VERSION ""

NS_ :

BS_:

BU_: VCU ADCU

BO_ 1544 mGpsAntStatus: 2 ADCU
 SG_ RelPosLength : 0|16@1- (0.001,0) [-32.768|32.767] "m"  VCU

BO_ 1543 mGpsLonRoverHP: 6 ADCU
 SG_ VehLonRover_hi : 16|32@1- (1,0) [-2147483648|2147483647] ""  VCU
 SG_ VehLonRover_lo : 0|16@1+ (1,0) [0|65535] ""  VCU

BO_ 1542 mGpsLatRoverHP: 6 ADCU
 SG_ VehLatRover_lo : 0|16@1+ (1,0) [0|65535] ""  VCU
 SG_ VehLatRover_hi : 16|32@1- (1,0) [-2147483648|2147483647] ""  VCU

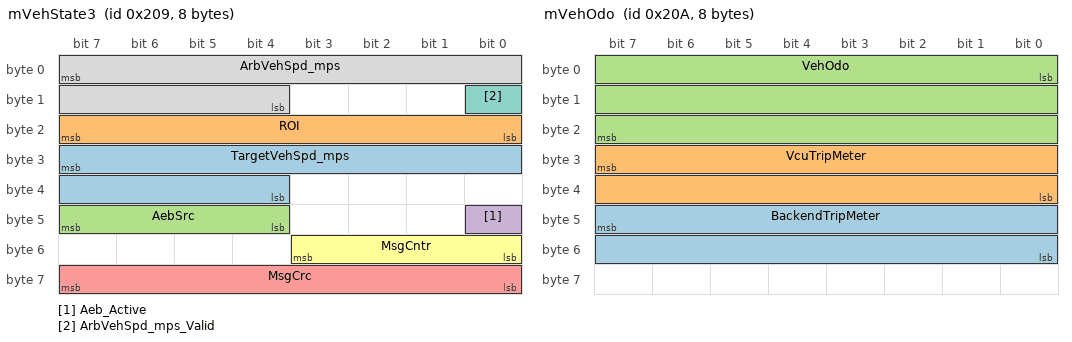
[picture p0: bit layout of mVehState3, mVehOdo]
BO_ 521 mVehState3: 8 VCU
 SG_ TargetVehSpd_mps : 31|12@0- (0.01,0) [-20.48|20.47] "mps"  ADCU
 SG_ ROI : 23|8@0- (0.01,0) [-1.28|1.27] ""  ADCU
 SG_ AebSrc : 47|4@0+ (1,0) [0|15] ""  ADCU
 SG_ Aeb_Active : 40|1@0+ (1,0) [0|0] ""  ADCU
 SG_ MsgCrc : 63|8@0+ (1,0) [0|255] ""  ADCU
 SG_ MsgCntr : 51|4@0+ (1,0) [0|15] ""  ADCU
 SG_ ArbVehSpd_mps_Valid : 8|1@0+ (1,0) [0|0] ""  ADCU
 SG_ ArbVehSpd_mps : 7|12@0- (0.01,0) [-20.48|20.47] "mps"  ADCU

BO_ 522 mVehOdo: 8 VCU
 SG_ BackendTripMeter : 47|16@0+ (0.001,0) [0|65.535] "Km"  ADCU
 SG_ VcuTripMeter : 31|16@0+ (0.001,0) [0|65.535] "Km"  ADCU
 SG_ VehOdo : 0|24@1+ (0.001,0) [0|16777.213] "Km"  ADCU

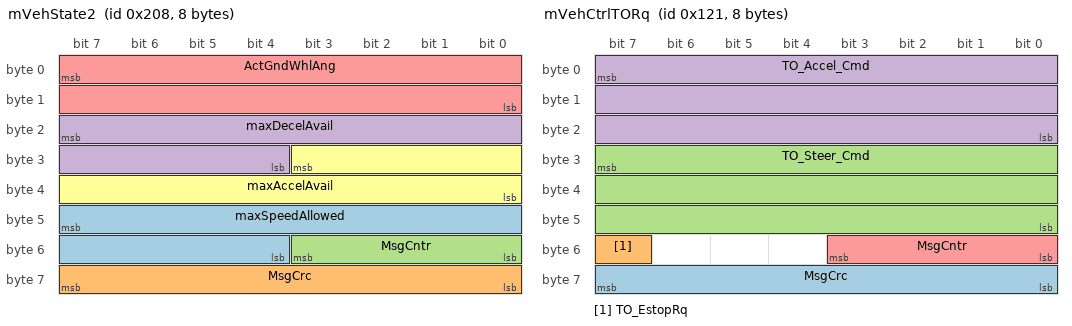
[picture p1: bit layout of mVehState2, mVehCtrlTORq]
BO_ 520 mVehState2: 8 VCU
 SG_ maxSpeedAllowed : 47|12@0+ (0.015625,0) [0|63.984375] "m/s"  ADCU
 SG_ MsgCrc : 56|8@1+ (1,0) [0|255] ""  ADCU
 SG_ MsgCntr : 48|4@1+ (1,0) [0|15] ""  ADCU
 SG_ maxDecelAvail : 23|12@0- (0.015625,0) [-32|31.984375] "m/s2"  ADCU
 SG_ ActGndWhlAng : 7|16@0- (0.01,0) [-327.68|327.67] "deg"  ADCU
 SG_ maxAccelAvail : 27|12@0- (0.015625,0) [-32|31.984375] "m/s2"  ADCU

BO_ 289 mVehCtrlTORq: 8 VCU
 SG_ MsgCrc : 63|8@0+ (1,0) [0|255] ""  ADCU
 SG_ TO_EstopRq : 55|1@0+ (1,0) [0|1] ""  ADCU
 SG_ TO_Steer_Cmd : 31|24@0- (1E-06,0) [-1|1] ""  ADCU
 SG_ TO_Accel_Cmd : 7|24@0- (1E-06,0) [-1|1] ""  ADCU
 SG_ MsgCntr : 51|4@0+ (1,0) [0|15] ""  ADCU

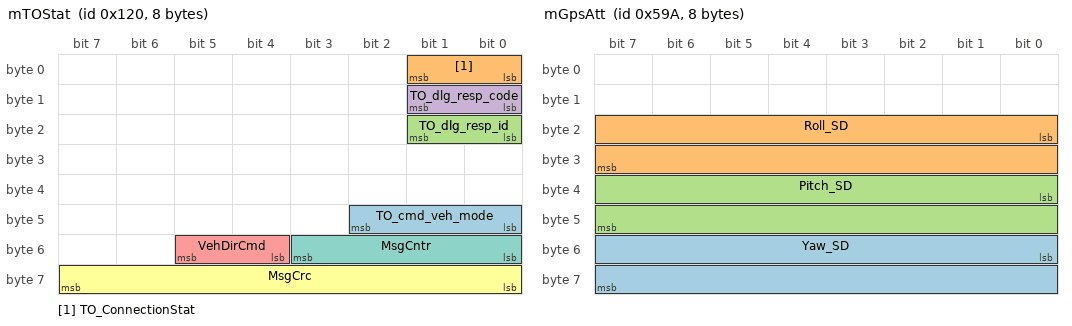
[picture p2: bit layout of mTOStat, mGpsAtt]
BO_ 288 mTOStat: 8 VCU
 SG_ TO_cmd_veh_mode : 42|3@0+ (1,0) [0|7] ""  ADCU
 SG_ TO_ConnectionStat : 1|2@0+ (1,0) [0|2] ""  ADCU
 SG_ TO_dlg_resp_id : 17|2@0+ (1,0) [0|3] ""  ADCU
 SG_ TO_dlg_resp_code : 9|2@0+ (1,0) [0|3] ""  ADCU
 SG_ VehDirCmd : 53|2@0+ (1,0) [0|0] ""  ADCU
 SG_ MsgCrc : 63|8@0+ (1,0) [0|255] ""  ADCU
 SG_ MsgCntr : 51|4@0+ (1,0) [0|15] ""  ADCU

BO_ 1541 mGpsLonHP: 8 ADCU
 SG_ VehLon_lo : 0|16@1+ (1,0) [0|65535] ""  VCU
 SG_ VehLon_hi : 16|32@1- (1,0) [-2147483648|2147483647] ""  VCU

BO_ 1540 mGpsLatHP: 8 ADCU
 SG_ VehLat_lo : 0|16@1+ (1,0) [0|65535] ""  VCU
 SG_ VehLat_hi : 16|32@1- (1,0) [-2147483648|2147483647] ""  VCU

BO_ 1429 mGpsSpdNorth: 8 ADCU
 SG_ NorthVelocity : 16|32@1- (0.001,0) [-2147483.648|2147483.645] "m/s"  VCU

BO_ 1428 mGpsSpdEast: 8 ADCU
 SG_ EastVelocity : 16|32@1- (0.001,0) [-2147483.648|2147483.645] "m/s"  VCU

BO_ 1434 mGpsAtt: 8 ADCU
 SG_ Yaw_SD : 48|16@1- (0.001,0) [0|0] ""  VCU
 SG_ Roll_SD : 16|16@1- (0.001,0) [0|0] ""  VCU
 SG_ Pitch_SD : 32|16@1- (0.001,0) [0|0] ""  VCU

BO_ 1425 mGpsSpdVeh: 8 ADCU
 SG_ gSpeed : 32|32@1+ (0.001,0) [0|100] "m/s"  VCU
 SG_ Yaw : 0|16@1+ (0.01,0) [0|655.35] "deg"  VCU

BO_ 1437 mGpsTime: 8 ADCU
 SG_ TimeStamp : 0|32@1+ (0.1,0) [0|429496729.5] "ms"  VCU
 SG_ UTC : 32|32@1+ (1,0) [0|4294967295] "s"  VCU

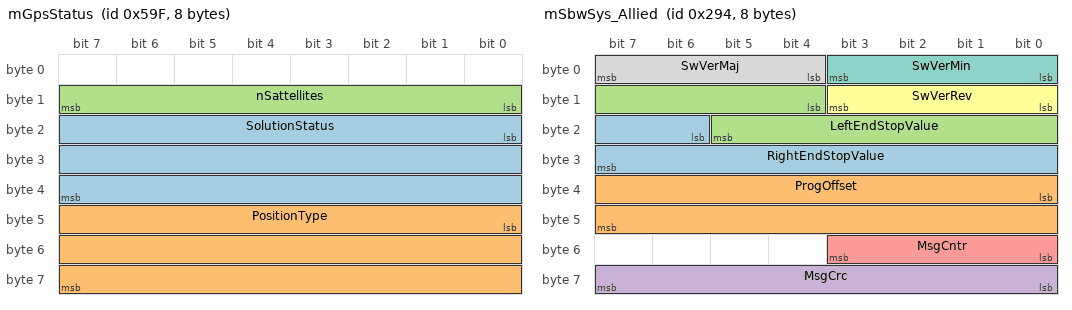
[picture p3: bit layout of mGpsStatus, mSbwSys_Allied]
BO_ 1439 mGpsStatus: 8 ADCU
 SG_ SolutionStatus : 16|24@1+ (1,0) [0|0] ""  VCU
 SG_ PositionType : 40|24@1+ (1,0) [0|0] ""  VCU
 SG_ nSattellites : 8|8@1+ (1,0) [0|0] ""  VCU

BO_ 660 mSbwSys_Allied: 8 VCU
 SG_ RightEndStopValue : 22|10@1+ (-1,0) [-1023|0] "deg"  ADCU
 SG_ ProgOffset : 32|16@1- (0.01,0) [-327.68|327.67] "deg"  ADCU
 SG_ LeftEndStopValue : 12|10@1+ (1,0) [0|1023] "deg"  ADCU
 SG_ MsgCrc : 56|8@1+ (1,0) [0|255] ""  ADCU
 SG_ MsgCntr : 48|4@1+ (1,0) [0|15] ""  ADCU
 SG_ SwVerRev : 8|4@1+ (1,0) [0|15] ""  ADCU
 SG_ SwVerMin : 0|4@1+ (1,0) [0|15] ""  ADCU
 SG_ SwVerMaj : 4|4@1+ (1,0) [0|15] ""  ADCU

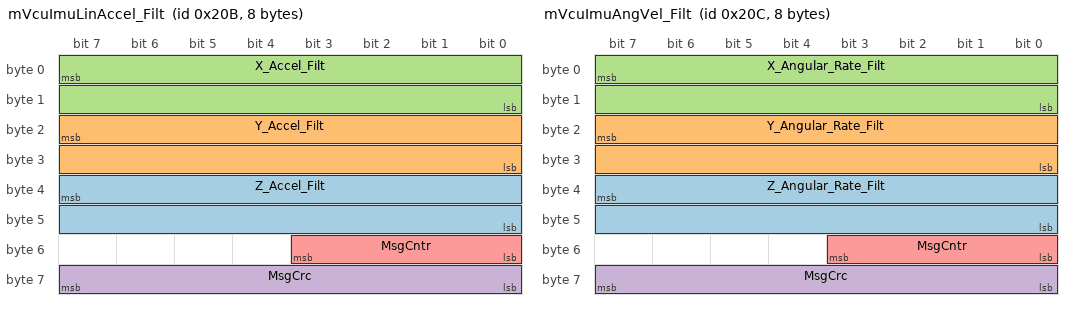
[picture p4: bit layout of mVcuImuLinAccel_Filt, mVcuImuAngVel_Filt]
BO_ 523 mVcuImuLinAccel_Filt: 8 VCU
 SG_ Z_Accel_Filt : 39|16@0- (0.001,0) [-32.768|32.767] "m/s2"  ADCU
 SG_ Y_Accel_Filt : 23|16@0- (0.001,0) [-32.768|32.767] "m/s2"  ADCU
 SG_ X_Accel_Filt : 7|16@0- (0.001,0) [-32.768|32.767] "m/s2"  ADCU
 SG_ MsgCrc : 63|8@0+ (1,0) [0|255] ""  ADCU
 SG_ MsgCntr : 51|4@0+ (1,0) [0|15] ""  ADCU

BO_ 524 mVcuImuAngVel_Filt: 8 VCU
 SG_ Z_Angular_Rate_Filt : 39|16@0- (0.01,0) [-327.68|327.67] "deg/s"  ADCU
 SG_ Y_Angular_Rate_Filt : 23|16@0- (0.01,0) [-327.68|327.67] "deg/s"  ADCU
 SG_ X_Angular_Rate_Filt : 7|16@0- (0.01,0) [-327.68|327.67] "deg/s"  ADCU
 SG_ MsgCrc : 63|8@0+ (1,0) [0|255] ""  ADCU
 SG_ MsgCntr : 51|4@0+ (1,0) [0|15] ""  ADCU

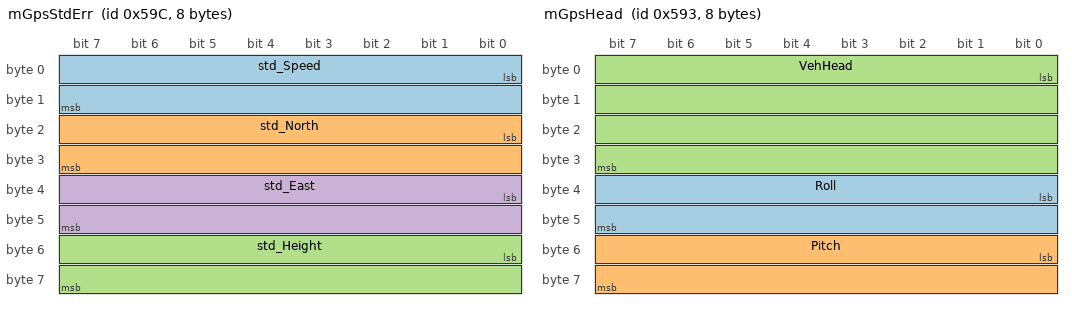
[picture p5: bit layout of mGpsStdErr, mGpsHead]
BO_ 1436 mGpsStdErr: 8 ADCU
 SG_ std_Speed : 0|16@1+ (0.001,0) [0|65.533] "m/s"  VCU
 SG_ std_North : 16|16@1+ (0.001,0) [0|65.533] "m"  VCU
 SG_ std_Height : 48|16@1+ (0.001,0) [0|65.533] "m"  VCU
 SG_ std_East : 32|16@1+ (0.001,0) [0|65.533] "m"  VCU

BO_ 1427 mGpsHead: 8 ADCU
 SG_ Roll : 32|16@1- (0.01,0) [-327.68|327.65] "deg"  VCU
 SG_ Pitch : 48|16@1- (0.01,0) [-327.68|327.65] "deg"  VCU
 SG_ VehHead : 0|32@1+ (1E-05,0) [0|360] "deg"  VCU

BO_ 1433 mGpsHeight: 8 ADCU
 SG_ Height : 16|32@1- (0.001,0) [-2147483.648|2147483.645] "m"  VCU

BO_ 1432 mGpsLat: 8 ADCU
 SG_ VehLat : 16|48@1- (3.27418092638254E-10,0) [-90|90] ""  VCU

BO_ 1431 mGpsLong: 8 ADCU
 SG_ VehLong : 16|48@1- (3.27418092638254E-10,0) [-180|180] ""  VCU

BO_ 519 mAdcuFaults: 8 ADCU
 SG_ Flt_EPVMC_Cameras : 0|1@0+ (1,0) [0|0] ""  VCU

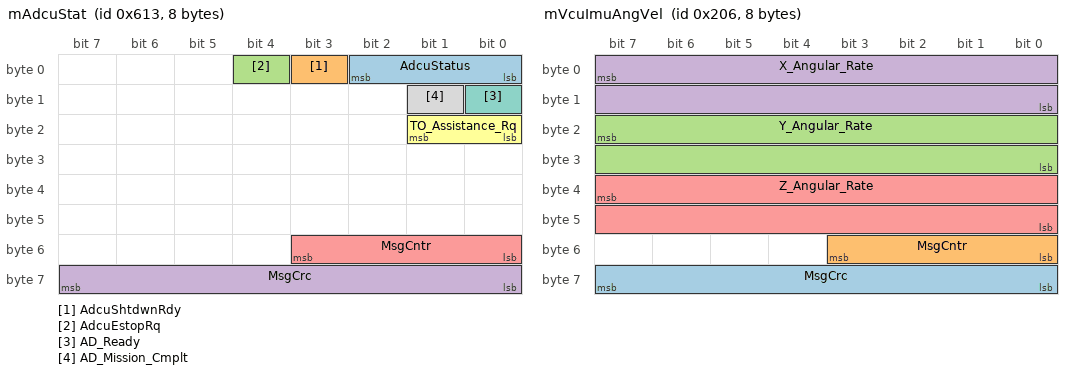
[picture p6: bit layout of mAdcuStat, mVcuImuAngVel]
BO_ 1555 mAdcuStat: 8 ADCU
 SG_ AdcuStatus : 2|3@0+ (1,0) [0|7] ""  VCU
 SG_ AdcuShtdwnRdy : 3|1@0+ (1,0) [0|1] ""  VCU
 SG_ AdcuEstopRq : 4|1@0+ (1,0) [0|1] ""  VCU
 SG_ MsgCrc : 63|8@0+ (1,0) [0|255] ""  VCU
 SG_ MsgCntr : 51|4@0+ (1,0) [0|15] ""  VCU
 SG_ TO_Assistance_Rq : 17|2@0+ (1,0) [0|2] ""  VCU
 SG_ AD_Ready : 8|1@0+ (1,0) [0|0] ""  VCU
 SG_ AD_Mission_Cmplt : 9|1@0+ (1,0) [0|1] ""  VCU

BO_ 518 mVcuImuAngVel: 8 VCU
 SG_ MsgCrc : 63|8@0+ (1,0) [0|255] ""  ADCU
 SG_ MsgCntr : 51|4@0+ (1,0) [0|15] ""  ADCU
 SG_ Y_Angular_Rate : 23|16@0- (0.01,0) [-327.68|327.67] "deg/s"  ADCU
 SG_ X_Angular_Rate : 7|16@0- (0.01,0) [-327.68|327.67] "deg/s"  ADCU
 SG_ Z_Angular_Rate : 39|16@0- (0.01,0) [-327.68|327.67] "deg/s"  ADCU

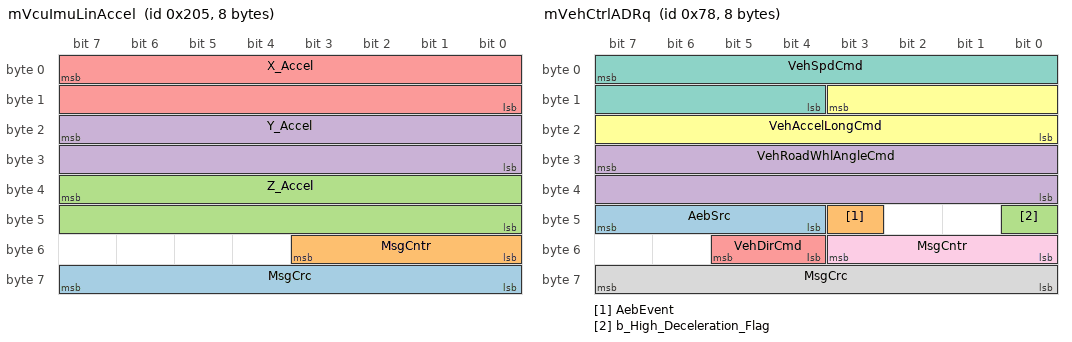
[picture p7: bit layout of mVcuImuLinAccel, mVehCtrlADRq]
BO_ 517 mVcuImuLinAccel: 8 VCU
 SG_ MsgCrc : 63|8@0+ (1,0) [0|255] ""  ADCU
 SG_ MsgCntr : 51|4@0+ (1,0) [0|15] ""  ADCU
 SG_ Z_Accel : 39|16@0- (0.001,0) [-32.768|32.767] "m/s2"  ADCU
 SG_ Y_Accel : 23|16@0- (0.001,0) [-32.768|32.767] "m/s2"  ADCU
 SG_ X_Accel : 7|16@0- (0.001,0) [-32.768|32.767] "m/s2"  ADCU

BO_ 120 mVehCtrlADRq: 8 ADCU
 SG_ AebSrc : 47|4@0+ (1,0) [0|15] ""  VCU
 SG_ AebEvent : 43|1@0+ (1,0) [0|1] ""  VCU
 SG_ b_High_Deceleration_Flag : 40|1@0+ (1,0) [0|1] ""  VCU
 SG_ VehRoadWhlAngleCmd : 31|16@0- (0.01,0) [-327.68|327.67] "deg"  VCU
 SG_ VehDirCmd : 53|2@0+ (1,0) [0|0] ""  VCU
 SG_ VehAccelLongCmd : 11|12@0- (0.015625,0) [-32|31.984375] "m/s2"  VCU
 SG_ VehSpdCmd : 7|12@0- (0.015625,0) [-64|63.96875] "m/s"  VCU
 SG_ MsgCrc : 63|8@0+ (1,0) [0|255] ""  VCU
 SG_ MsgCntr : 51|4@0+ (1,0) [0|15] ""  VCU

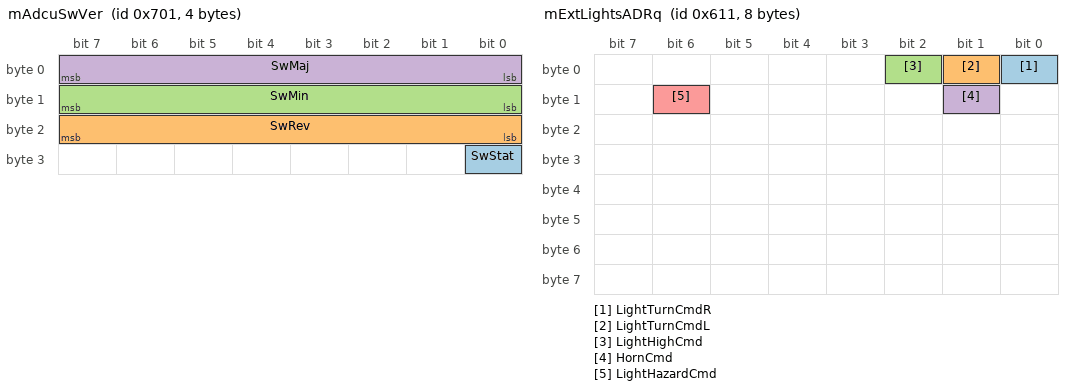
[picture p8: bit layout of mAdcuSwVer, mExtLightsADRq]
BO_ 1793 mAdcuSwVer: 4 ADCU
 SG_ SwStat : 24|1@0+ (1,0) [0|1] ""  VCU
 SG_ SwRev : 23|8@0+ (1,0) [0|255] ""  VCU
 SG_ SwMin : 15|8@0+ (1,0) [0|255] ""  VCU
 SG_ SwMaj : 7|8@0+ (1,0) [0|255] ""  VCU

BO_ 1553 mExtLightsADRq: 8 ADCU
 SG_ LightTurnCmdR : 0|1@1+ (1,0) [0|1] ""  VCU
 SG_ LightTurnCmdL : 1|1@1+ (1,0) [0|1] ""  VCU
 SG_ LightHighCmd : 2|1@1+ (1,0) [0|1] ""  VCU
 SG_ HornCmd : 9|1@1+ (1,0) [0|1] ""  VCU
 SG_ LightHazardCmd : 14|1@0+ (1,0) [0|1] ""  VCU

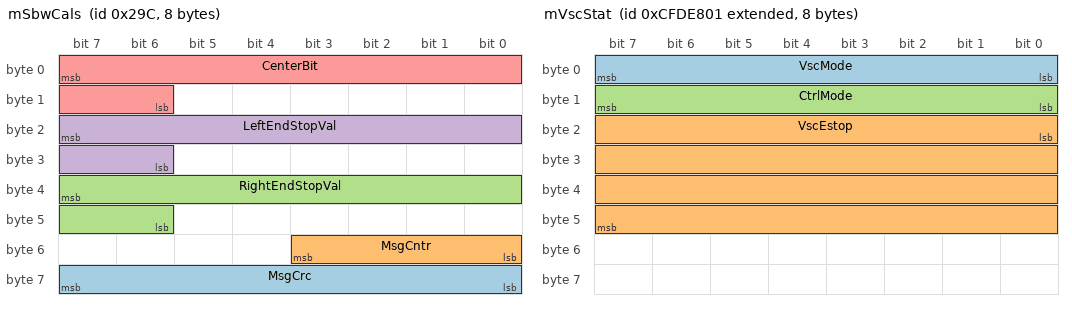
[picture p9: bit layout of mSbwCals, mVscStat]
BO_ 668 mSbwCals: 8 VCU
 SG_ MsgCrc : 63|8@0+ (1,0) [0|255] ""  ADCU
 SG_ MsgCntr : 51|4@0+ (1,0) [0|15] ""  ADCU
 SG_ RightEndStopVal : 39|10@0+ (1,0) [0|1023] "Count"  ADCU
 SG_ LeftEndStopVal : 23|10@0+ (1,0) [0|1023] "Count"  ADCU
 SG_ CenterBit : 7|10@0+ (1,0) [0|1023] "Count"  ADCU

BO_ 2365450241 mVscStat: 8 VCU
 SG_ VscMode : 0|8@1+ (1,0) [0|255] ""  ADCU
 SG_ VscEstop : 16|32@1+ (1,0) [0|4294967295] ""  ADCU
 SG_ CtrlMode : 8|8@1+ (1,0) [0|255] ""  ADCU

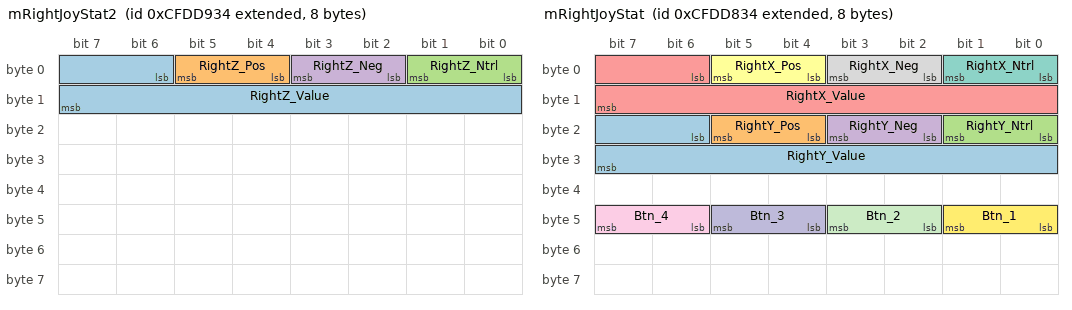
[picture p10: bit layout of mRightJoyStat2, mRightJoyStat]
BO_ 2365446452 mRightJoyStat2: 8 VCU
 SG_ RightZ_Value : 6|10@1+ (1,0) [0|1023] ""  ADCU
 SG_ RightZ_Pos : 4|2@1+ (1,0) [0|3] ""  ADCU
 SG_ RightZ_Ntrl : 0|2@1+ (1,0) [0|3] ""  ADCU
 SG_ RightZ_Neg : 2|2@1+ (1,0) [0|3] ""  ADCU

BO_ 2365446196 mRightJoyStat: 8 VCU
 SG_ RightY_Value : 22|10@1+ (1,0) [0|1023] ""  ADCU
 SG_ RightY_Pos : 20|2@1+ (1,0) [0|3] ""  ADCU
 SG_ RightY_Ntrl : 16|2@1+ (1,0) [0|3] ""  ADCU
 SG_ RightY_Neg : 18|2@1+ (1,0) [0|3] ""  ADCU
 SG_ RightX_Value : 6|10@1+ (1,0) [0|1023] ""  ADCU
 SG_ RightX_Pos : 4|2@1+ (1,0) [0|3] ""  ADCU
 SG_ RightX_Ntrl : 0|2@1+ (1,0) [0|3] ""  ADCU
 SG_ RightX_Neg : 2|2@1+ (1,0) [0|3] ""  ADCU
 SG_ Btn_4 : 46|2@1+ (1,0) [0|3] ""  ADCU
 SG_ Btn_3 : 44|2@1+ (1,0) [0|3] ""  ADCU
 SG_ Btn_2 : 42|2@1+ (1,0) [0|3] ""  ADCU
 SG_ Btn_1 : 40|2@1+ (1,0) [0|3] ""  ADCU

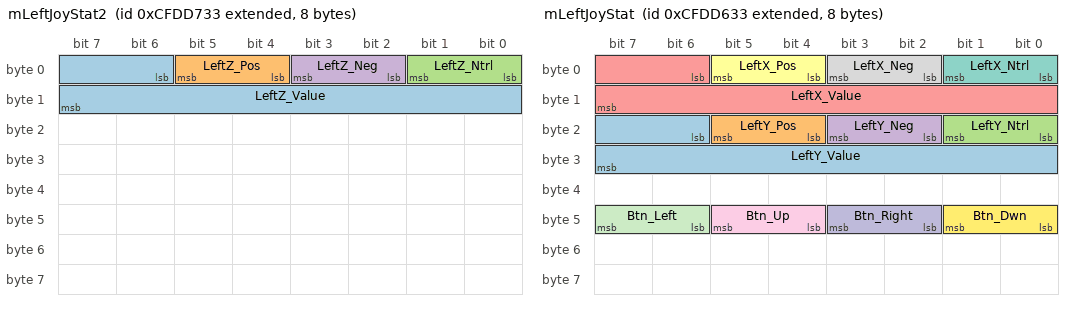
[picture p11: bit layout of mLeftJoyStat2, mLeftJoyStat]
BO_ 2365445939 mLeftJoyStat2: 8 VCU
 SG_ LeftZ_Value : 6|10@1+ (1,0) [0|1023] ""  ADCU
 SG_ LeftZ_Pos : 4|2@1+ (1,0) [0|3] ""  ADCU
 SG_ LeftZ_Ntrl : 0|2@1+ (1,0) [0|3] ""  ADCU
 SG_ LeftZ_Neg : 2|2@1+ (1,0) [0|3] ""  ADCU

BO_ 2365445683 mLeftJoyStat: 8 VCU
 SG_ LeftY_Value : 22|10@1+ (1,0) [0|1023] ""  ADCU
 SG_ LeftY_Pos : 20|2@1+ (1,0) [0|3] ""  ADCU
 SG_ LeftY_Ntrl : 16|2@1+ (1,0) [0|3] ""  ADCU
 SG_ LeftY_Neg : 18|2@1+ (1,0) [0|3] ""  ADCU
 SG_ LeftX_Value : 6|10@1+ (1,0) [0|1023] ""  ADCU
 SG_ LeftX_Pos : 4|2@1+ (1,0) [0|3] ""  ADCU
 SG_ LeftX_Ntrl : 0|2@1+ (1,0) [0|3] ""  ADCU
 SG_ LeftX_Neg : 2|2@1+ (1,0) [0|3] ""  ADCU
 SG_ Btn_Up : 44|2@1+ (1,0) [0|3] ""  ADCU
 SG_ Btn_Right : 42|2@1+ (1,0) [0|3] ""  ADCU
 SG_ Btn_Left : 46|2@1+ (1,0) [0|3] ""  ADCU
 SG_ Btn_Dwn : 40|2@1+ (1,0) [0|3] ""  ADCU

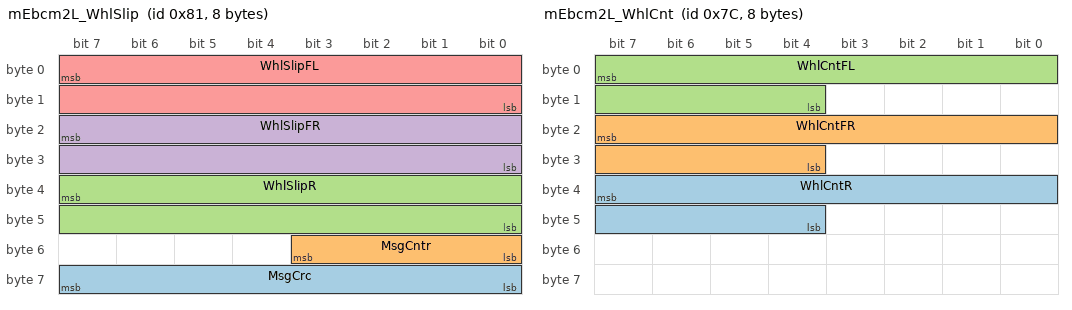
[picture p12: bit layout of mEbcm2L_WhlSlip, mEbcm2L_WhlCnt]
BO_ 129 mEbcm2L_WhlSlip: 8 VCU
 SG_ MsgCrc : 63|8@0+ (1,0) [0|255] ""  ADCU
 SG_ MsgCntr : 51|4@0+ (1,0) [0|15] ""  ADCU
 SG_ WhlSlipR : 39|16@0- (0.01,0) [-100|327.67] "Pct"  ADCU
 SG_ WhlSlipFR : 23|16@0- (0.01,0) [-100|327.67] "Pct"  ADCU
 SG_ WhlSlipFL : 7|16@0- (0.01,0) [-100|327.67] "Pct"  ADCU

BO_ 124 mEbcm2L_WhlCnt: 8 VCU
 SG_ WhlCntR : 39|12@0+ (1,0) [0|4093] "Count"  ADCU
 SG_ WhlCntFR : 23|12@0+ (1,0) [0|4093] "Count"  ADCU
 SG_ WhlCntFL : 7|12@0+ (1,0) [0|4093] "Count"  ADCU

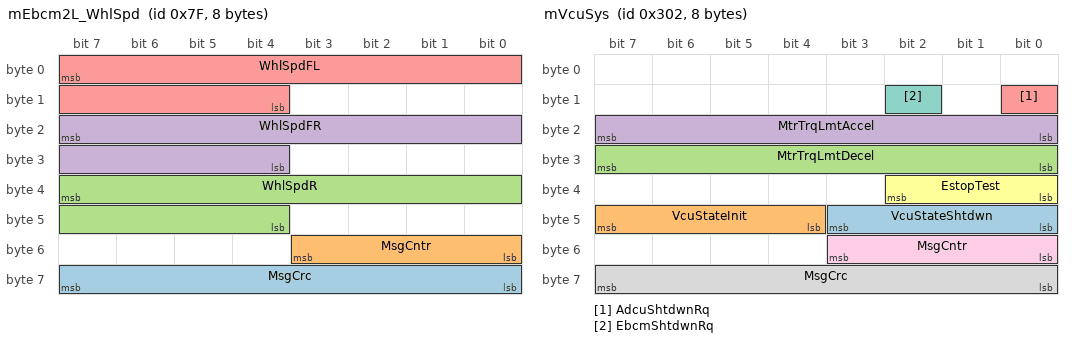
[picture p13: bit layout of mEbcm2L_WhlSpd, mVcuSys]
BO_ 127 mEbcm2L_WhlSpd: 8 VCU
 SG_ MsgCrc : 63|8@0+ (1,0) [0|255] ""  ADCU
 SG_ MsgCntr : 51|4@0+ (1,0) [0|15] ""  ADCU
 SG_ WhlSpdR : 39|12@0- (0.01,0) [-20.48|20.45] "m/s"  ADCU
 SG_ WhlSpdFR : 23|12@0- (0.01,0) [-20.48|20.45] "m/s"  ADCU
 SG_ WhlSpdFL : 7|12@0- (0.01,0) [-20.48|20.45] "m/s"  ADCU

BO_ 770 mVcuSys: 8 VCU
 SG_ VcuStateShtdwn : 43|4@0+ (1,0) [0|0] ""  VCU
 SG_ VcuStateInit : 47|4@0+ (1,0) [0|0] ""  VCU
 SG_ MtrTrqLmtDecel : 24|8@1+ (1,0) [0|255] "Nm"  VCU
 SG_ MtrTrqLmtAccel : 16|8@1+ (1,0) [0|255] "Nm"  VCU
 SG_ AdcuShtdwnRq : 8|1@0+ (1,0) [0|1] ""  VCU,ADCU
 SG_ EstopTest : 32|3@1+ (1,0) [0|7] ""  VCU
 SG_ EbcmShtdwnRq : 10|1@0+ (1,0) [0|1] ""  VCU
 SG_ MsgCrc : 63|8@0+ (1,0) [0|255] ""  VCU
 SG_ MsgCntr : 51|4@0+ (1,0) [0|15] ""  VCU

BO_ 516 mVcuFaults: 8 VCU
 SG_ Flt_InvalidGearRq : 61|1@0+ (1,0) [0|1] ""  ADCU
 SG_ Flt_LocEpb : 54|2@1+ (1,0) [0|3] ""  ADCU
 SG_ Flt_LocTo : 34|2@1+ (1,0) [0|3] ""  ADCU
 SG_ Flt_LocBe : 32|2@1+ (1,0) [0|3] ""  ADCU
 SG_ Flt_12vSys : 26|1@1+ (1,0) [0|1] ""  ADCU
 SG_ Flt_WriteEeprom : 24|1@1+ (1,0) [0|1] ""  ADCU
 SG_ Flt_ReadEeprom : 25|1@1+ (1,0) [0|1] ""  ADCU
 SG_ Flt_BrkSafeSys : 58|1@1+ (1,0) [0|1] ""  ADCU
 SG_ Flt_SafeCircuit : 5|1@1+ (1,0) [0|1] ""  ADCU
 SG_ Flt_MstrSwitch : 4|1@1+ (1,0) [0|1] ""  ADCU
 SG_ Flt_CntctrStat : 59|2@1+ (1,0) [0|1] ""  ADCU
 SG_ Flt_BrkPrsr : 56|1@1+ (1,0) [0|1] ""  ADCU
 SG_ Flt_WhdEnbl : 62|1@1+ (1,0) [0|1] ""  ADCU
 SG_ Flt_SbwEnbl : 47|1@1+ (1,0) [0|1] ""  ADCU
 SG_ Flt_SafeSteer : 52|2@1+ (1,0) [0|3] ""  ADCU
 SG_ Flt_SafeProp : 50|2@1+ (1,0) [0|3] ""  ADCU
 SG_ Flt_SafeExtLight : 48|2@1+ (1,0) [0|3] ""  ADCU
 SG_ Flt_EpbSys : 57|1@1+ (1,0) [0|1] ""  ADCU
 SG_ Flt_DcdcEnbl : 63|1@1+ (1,0) [0|1] ""  ADCU
 SG_ Flt_48Volt : 2|2@1+ (1,0) [0|3] ""  ADCU
 SG_ Flt_12Volt : 0|2@1+ (1,0) [0|3] ""  ADCU
 SG_ Flt_LocWhd : 6|2@1+ (1,0) [0|3] ""  ADCU
 SG_ Flt_LocTc : 22|2@1+ (1,0) [0|3] ""  ADCU
 SG_ Flt_LocSbw : 20|2@1+ (1,0) [0|3] ""  ADCU
 SG_ Flt_LocAVAS : 18|2@1+ (1,0) [0|3] ""  ADCU
 SG_ Flt_LocVsc : 16|2@1+ (1,0) [0|3] ""  ADCU
 SG_ Flt_LocEss : 14|2@1+ (1,0) [0|3] ""  ADCU
 SG_ Flt_LocEbcm2 : 12|2@1+ (1,0) [0|3] ""  ADCU
 SG_ Flt_LocEbcm1 : 10|2@1+ (1,0) [0|3] ""  ADCU
 SG_ Flt_LocAdcu : 8|2@1+ (1,0) [0|3] ""  ADCU
 SG_ Flt_LocLrr : 40|1@1+ (1,0) [0|1] ""  ADCU
 SG_ Flt_KeypadLight : 46|1@1+ (1,0) [0|1] ""  ADCU
 SG_ Flt_KeypadC : 45|1@1+ (1,0) [0|1] ""  ADCU
 SG_ Flt_Keypad4 : 44|1@1+ (1,0) [0|1] ""  ADCU
 SG_ Flt_LocFcmCan : 43|1@1+ (1,0) [0|1] ""  ADCU
 SG_ Flt_ImuRst : 42|1@1+ (1,0) [0|1] ""  ADCU
 SG_ Flt_ImuSns : 41|1@1+ (1,0) [0|1] ""  ADCU
 SG_ Flt_Bay2Pwr12v : 39|1@1+ (1,0) [0|1] ""  ADCU
 SG_ Flt_Bay2MtrPos : 37|1@1+ (1,0) [0|1] ""  ADCU
 SG_ Flt_Bay2Mtr : 38|1@1+ (1,0) [0|1] ""  ADCU
 SG_ Flt_Bay2BeltSns : 36|1@1+ (1,0) [0|1] ""  ADCU
 SG_ Flt_Bay1Pwr12v : 31|1@1+ (1,0) [0|1] ""  ADCU
 SG_ Flt_Bay1MtrPos : 29|1@1+ (1,0) [0|1] ""  ADCU
 SG_ Flt_Bay1Mtr : 30|1@1+ (1,0) [0|1] ""  ADCU
 SG_ Flt_Bay1BeltSns : 28|1@1+ (1,0) [0|1] ""  ADCU

BO_ 514 mVehState: 8 VCU
 SG_ SBW_RtEndStopReached : 28|1@0+ (1,0) [0|1] ""  ADCU
 SG_ SBW_LfEndStopReached : 29|1@0+ (1,0) [0|1] ""  ADCU
 SG_ Invld_GearRq : 55|1@0+ (1,0) [0|1] ""  ADCU
 SG_ EstopDetected : 41|1@0+ (1,0) [0|1] ""  ADCU
 SG_ Tether_Connected : 43|1@0+ (1,0) [0|0] ""  ADCU
 SG_ VehParkRq : 42|1@0- (1,0) [0|0] ""  ADCU
 SG_ ArbVehSpdValid : 40|1@0+ (1,0) [0|0] ""  ADCU
 SG_ ArbVehSpd : 39|12@0- (0.02,0) [-40.96|40.94] "kph"  ADCU
 SG_ GearRq : 24|2@1+ (1,0) [0|3] ""  ADCU
 SG_ GearChangeParkAllow : 30|1@0+ (1,0) [0|0] ""  ADCU
 SG_ TO_Allowed : 52|1@0+ (1,0) [0|0] ""  ADCU
 SG_ LOS_Allowed : 54|1@0+ (1,0) [0|0] ""  ADCU
 SG_ AD_Allowed : 53|1@0+ (1,0) [0|0] ""  ADCU
 SG_ GearChangeDrvRevAllow : 31|1@0+ (1,0) [0|0] ""  ADCU
 SG_ GearAct : 26|2@1+ (1,0) [0|3] ""  ADCU
 SG_ MsgCrc : 63|8@0+ (1,0) [0|255] ""  ADCU
 SG_ MsgCntr : 48|4@1+ (1,0) [0|15] ""  ADCU
 SG_ VehDte : 6|10@1+ (0.1,0) [0|102.3] "Km"  ADCU
 SG_ LvVolt : 16|8@1+ (0.1,0) [0|25.5] "V"  ADCU
 SG_ CrashSns : 5|1@1+ (1,0) [0|1] ""  ADCU
 SG_ VcuEstopSns : 4|1@1+ (1,0) [0|1] ""  ADCU
 SG_ VehState : 0|4@1+ (1,0) [0|15] ""  ADCU

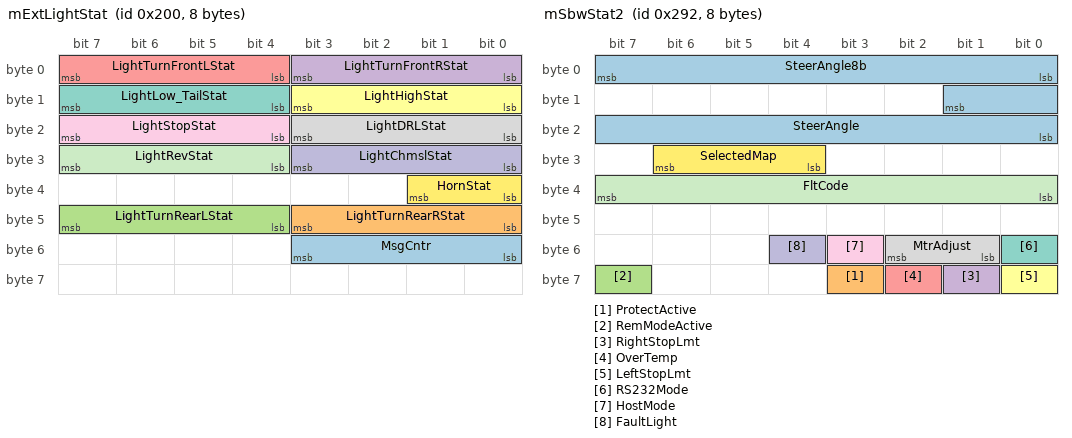
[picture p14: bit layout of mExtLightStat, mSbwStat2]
BO_ 512 mExtLightStat: 8 VCU
 SG_ MsgCntr : 51|4@0+ (1,0) [0|15] ""  ADCU
 SG_ LightTurnRearRStat : 40|4@1+ (1,0) [0|3] ""  ADCU
 SG_ LightTurnRearLStat : 44|4@1+ (1,0) [0|3] ""  ADCU
 SG_ LightTurnFrontRStat : 0|4@1+ (1,0) [0|3] ""  ADCU
 SG_ LightTurnFrontLStat : 4|4@1+ (1,0) [0|3] ""  ADCU
 SG_ LightHighStat : 8|4@1+ (1,0) [0|3] ""  ADCU
 SG_ LightLow_TailStat : 12|4@1+ (1,0) [0|3] ""  ADCU
 SG_ LightDRLStat : 16|4@1+ (1,0) [0|3] ""  ADCU
 SG_ LightStopStat : 20|4@1+ (1,0) [0|3] ""  ADCU
 SG_ LightChmslStat : 24|4@1+ (1,0) [0|3] ""  ADCU
 SG_ LightRevStat : 28|4@1+ (1,0) [0|3] ""  ADCU
 SG_ HornStat : 32|2@1+ (1,0) [0|3] ""  ADCU

BO_ 658 mSbwStat2: 8 VCU
 SG_ SteerAngle8b : 7|8@0+ (1,0) [0|255] "Count"  ADCU
 SG_ ProtectActive : 59|1@1+ (1,0) [0|1] ""  ADCU
 SG_ RemModeActive : 63|1@1+ (1,0) [0|1] ""  ADCU
 SG_ RightStopLmt : 57|1@1+ (1,0) [0|1] ""  ADCU
 SG_ OverTemp : 58|1@1+ (1,0) [0|1] ""  ADCU
 SG_ LeftStopLmt : 56|1@1+ (1,0) [0|1] ""  ADCU
 SG_ RS232Mode : 48|1@1+ (1,0) [0|0] ""  ADCU
 SG_ MtrAdjust : 49|2@1+ (1,0) [0|3] ""  ADCU
 SG_ HostMode : 51|1@1+ (1,0) [0|1] ""  ADCU
 SG_ FaultLight : 52|1@1+ (1,0) [0|1] ""  ADCU
 SG_ FltCode : 32|8@1+ (1,0) [0|255] ""  ADCU
 SG_ SelectedMap : 28|3@1+ (1,0) [0|7] ""  ADCU
 SG_ SteerAngle : 9|10@0+ (1,0) [0|1023] "Count"  ADCU

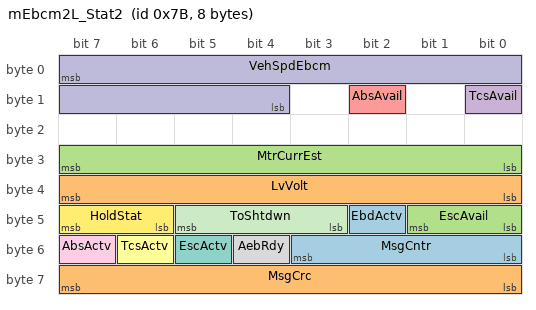
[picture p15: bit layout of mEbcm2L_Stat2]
BO_ 123 mEbcm2L_Stat2: 8 VCU
 SG_ EbdActv : 42|1@0+ (1,0) [0|1] ""  ADCU
 SG_ MsgCrc : 63|8@0+ (1,0) [0|255] ""  ADCU
 SG_ EscAvail : 41|2@0+ (1,0) [0|3] ""  ADCU
 SG_ TcsAvail : 8|1@0+ (1,0) [0|1] ""  ADCU
 SG_ AbsAvail : 10|1@0+ (1,0) [0|1] ""  ADCU
 SG_ TcsActv : 54|1@0+ (1,0) [0|1] ""  ADCU
 SG_ EscActv : 53|1@0+ (1,0) [0|1] ""  ADCU
 SG_ AebRdy : 52|1@0+ (1,0) [0|1] ""  ADCU
 SG_ AbsActv : 55|1@0+ (1,0) [0|1] ""  ADCU
 SG_ VehSpdEbcm : 7|12@0- (0.01,0) [-20.48|20.45] "m/s"  ADCU
 SG_ ToShtdwn : 45|3@0+ (1,0) [0|7] ""  ADCU
 SG_ HoldStat : 47|2@0+ (1,0) [0|3] ""  ADCU
 SG_ MsgCntr : 51|4@0+ (1,0) [0|15] ""  ADCU
 SG_ LvVolt : 39|8@0+ (0.1,0) [0|25.5] "V"  ADCU
 SG_ MtrCurrEst : 31|8@0+ (1,0) [0|255] "A"  ADCU

CM_ BU_ VCU "Vehicle Control Unit";
CM_ BU_ ADCU "Autonomous Driving Control Module";
CM_ BO_ 1544 "Previously named 'Ublox_VehInfo'";
CM_ BO_ 1543 "Previously named 'Ublox_Attitude'";
CM_ BO_ 1542 "Previously named 'Ublox_Attitude'";
CM_ BO_ 521 "Vehicle level data";
CM_ SG_ 521 TargetVehSpd_mps "VCU Arbitrated Vehicle Speed";
CM_ SG_ 521 ROI "Roll Over Index";
CM_ SG_ 521 AebSrc "CGVCU determined source of Aeb Trigger .";
CM_ SG_ 521 Aeb_Active "AEB Event is detected and VCU is actively engaging AEB.";
CM_ SG_ 521 MsgCrc "mVehState3 Message Checksum (E2E data ID: 0x54)";
CM_ SG_ 521 ArbVehSpd_mps_Valid "Validity for Arbitrated Vehicle Speed.";
CM_ SG_ 521 ArbVehSpd_mps "VCU Arbitrated Vehicle Speed";
CM_ BO_ 522 "Odometer signals.";
CM_ SG_ 522 BackendTripMeter "FMS Trip Meter";
CM_ BO_ 520 "Vehicle level data.";
CM_ SG_ 520 maxSpeedAllowed "Maximum Speed Allowed based on ESS Discharge capacity.";
CM_ SG_ 520 MsgCrc "mVehState2 Message Checksum (E2E data ID: 0x53)";
CM_ SG_ 520 maxDecelAvail "Maximum Deceleration Rate Available.";
CM_ SG_ 520 ActGndWhlAng "Actual Road Wheel Angle.  Positive values are to the left in vehicle coordinate system.";
CM_ SG_ 520 maxAccelAvail "Maximum Acceleration available based on ESS Discharge capacity.";
CM_ BO_ 289 "Vehicle Control Request from TeleOperations.";
CM_ SG_ 289 MsgCrc "mVehCtrlTORq Message Checksum (E2E data ID: 0x42)";
CM_ BO_ 288 "TeleOperations Status";
CM_ SG_ 288 TO_dlg_resp_id "0 = TeleOps has not responded yet.
1 = Go - Continue AD Control
2 = No Go.  TeleOps has Acknowledged and will take remote control based on priority.";
CM_ SG_ 288 TO_dlg_resp_code "Response from TO Operator to Allow / Deny AD Control Request.";
CM_ SG_ 288 VehDirCmd "Gear direction request from TO.";
CM_ SG_ 288 MsgCrc "mTOStat Message Checksum (E2E data ID: 0x41)";
CM_ BO_ 1541 "Previously named 'Ublox_Attitude'";
CM_ BO_ 1540 "Previously named 'Ublox_Attitude'";
CM_ BO_ 1429 "Previously named 'Ublox_VelN'";
CM_ BO_ 1428 "Previously named 'Ublox_VelE'";
CM_ BO_ 1434 "Previously named 'Ublox_Attitude'";
CM_ BO_ 1425 "Previously named 'Ublox_VehInfo'";
CM_ BO_ 1437 "Previously named 'Ublox_Time'";
CM_ BO_ 1439 "Previously named 'Ublox_Status'";
CM_ BO_ 660 "Software version and Calibrated Values from SBW.";
CM_ SG_ 660 RightEndStopValue "Calibrated Right End Stop value.";
CM_ SG_ 660 ProgOffset "Programmed offset between Raw Position and Corrected Position.";
CM_ SG_ 660 LeftEndStopValue "Calibrated Left End Stop value.";
CM_ SG_ 660 MsgCrc "mSbwSys  Message Checksum (Autosar Profile 1 - E2E data ID: 0x17)";
CM_ SG_ 660 MsgCntr "Message Counter 0..14
15 indicates fault";
CM_ SG_ 660 SwVerRev "Major Software version number.";
CM_ SG_ 660 SwVerMin "Minor software version number.";
CM_ SG_ 660 SwVerMaj "Major Software version number.";
CM_ BO_ 523 "IMU Data after Filter";
CM_ SG_ 523 Z_Accel_Filt "Untransformed";
CM_ SG_ 523 Y_Accel_Filt "Untransformed";
CM_ SG_ 523 X_Accel_Filt "Untransformed";
CM_ SG_ 523 MsgCrc "mVcuImuLinAccel_Filt Message Checksum (E2E data ID: 0x55)";
CM_ BO_ 524 "IMU Data after Filter";
CM_ SG_ 524 MsgCrc "mVcuImuAngVel_Filt Message Checksum (E2E data ID: 0x56)";
CM_ BO_ 1436 "Previously named 'Ublox_STD'";
CM_ BO_ 1427 "Previously named 'Ublox_Heading'";
CM_ BO_ 1433 "Previously named 'Ublox_Height'";
CM_ BO_ 1432 "Previously named 'Ublox_Lat'";
CM_ BO_ 1431 "Previously named 'Ublox_Lon'";
CM_ BO_ 519 "ADCU fault reporting";
CM_ SG_ 519 Flt_EPVMC_Cameras "Failure of Surround View Cameras";
CM_ BO_ 1555 "ADCU Status";
CM_ SG_ 1555 AdcuStatus "Overall status of ADCU.";
CM_ SG_ 1555 AdcuShtdwnRdy "Flag indicating that ADCU has performed shutdown routine and is ready for power to be removed.";
CM_ SG_ 1555 AdcuEstopRq "Flag indicating Emergency Stop condition (not AEB).";
CM_ SG_ 1555 MsgCrc "mAdcuStat Message Checksum (E2E data ID: 0xA6)";
CM_ SG_ 1555 MsgCntr "Check the MessageCounter consistency at least on every message reception";
CM_ SG_ 1555 TO_Assistance_Rq "ADCU is requesting assistance from TO operator.  Since signal is passed through VCU, generally it will reflect the value as received from ADCU.  If VCU has lost communication with ADU, VCU may directly request Remote Control to TO.";
CM_ SG_ 1555 AD_Ready "Flag indicating that AD is ready to take control of LMDD.";
CM_ SG_ 1555 AD_Mission_Cmplt "Flag indicating AD Mission Completion status.";
CM_ BO_ 518 "Untransformed ";
CM_ SG_ 518 MsgCrc "mVcuImuAngVel Message Checksum (E2E data ID: 0x52)";
CM_ BO_ 517 "Untransformed Acceleration.";
CM_ SG_ 517 MsgCrc "mVcuImuLinAccel Message Checksum (E2E data ID: 0x51)";
CM_ SG_ 517 Z_Accel "Untransformed";
CM_ SG_ 517 Y_Accel "Untransformed";
CM_ SG_ 517 X_Accel "Untransformed";
CM_ BO_ 120 "Vehicle Control Request from ADCU.";
CM_ SG_ 120 AebSrc "Source of Aeb Trigger from AD.";
CM_ SG_ 120 AebEvent "Notification that AD has sensed an AEB condition and vehicle should immediately stop.";
CM_ SG_ 120 b_High_Deceleration_Flag "Signal to indicate ADCU is requesting a high deleration rate due to sensor fusion data.  Not to be used for AEB function.";
CM_ SG_ 120 VehRoadWhlAngleCmd "Road Wheel Angle command from ADCU (deg).";
CM_ SG_ 120 VehDirCmd "Gear direction request from ADCU.";
CM_ SG_ 120 VehAccelLongCmd "Longitudinal Acceleration command from ADCU.";
CM_ SG_ 120 VehSpdCmd "Equivalent to Set Speed in ACC Function.";
CM_ SG_ 120 MsgCrc "mVehCtrlADRq  Message Checksum (E2E data ID: 0x40)";
CM_ BO_ 1793 "ADCU Software version.";
CM_ SG_ 1793 SwStat "Release status of software.";
CM_ SG_ 1793 SwRev "Revision of Software version.";
CM_ SG_ 1793 SwMin "Minor version of Software.";
CM_ SG_ 1793 SwMaj "Major version of Software.";
CM_ BO_ 1553 "Previously named 'ExtLightsCmd'";
CM_ SG_ 1553 LightTurnCmdR "Right Turn Signal Command from ADCU.";
CM_ SG_ 1553 LightTurnCmdL "Left Turn Signal request from ADCU.";
CM_ SG_ 1553 LightHighCmd "High Beam Light Command from ADCU.";
CM_ SG_ 1553 HornCmd "Horn is requested from ADCU.";
CM_ SG_ 1553 LightHazardCmd "Hazard Light Command from ADCU.";
CM_ BO_ 668 "SBW calibrated values of Center Bit Position, Left and Right End Stops";
CM_ SG_ 668 MsgCrc "mSbwCals Message Checksum (E2E data ID: 0x11)";
CM_ SG_ 668 RightEndStopVal "SBW - Position Value of Left End Stop";
CM_ SG_ 668 LeftEndStopVal "SBW - Position Value of Left End Stop";
CM_ SG_ 668 CenterBit "SBW - center bit position";
CM_ BO_ 2365450241 "Status message from VSS.";
CM_ SG_ 2365450241 CtrlMode "Identifies the desired motor control mode";
CM_ BO_ 2365446452 "Right Joystick from VSS";
CM_ BO_ 2365446196 "Right Joystick from VSS";
CM_ BO_ 2365445939 "Left Joystick from VSS";
CM_ BO_ 2365445683 "Left Joystick from VSS";
CM_ BO_ 129 "Downstream EBCM (Lower)";
CM_ SG_ 129 MsgCrc "mEbcm2L_WhlSlip Message Checksum (E2E data ID: 0x24)";
CM_ BO_ 124 "Downstream EBCM (Lower)";
CM_ SG_ 124 WhlCntR "Accumulative wrap-around wheel speed sensor pulse counter.  36 pulses per revolution";
CM_ SG_ 124 WhlCntFR "Accumulative wrap-around wheel speed sensor pulse counter.  36 pulses per revolution";
CM_ SG_ 124 WhlCntFL "Accumulative wrap-around wheel speed sensor pulse counter.  36 pulses per revolution";
CM_ BO_ 127 "Downstream EBCM (Lower)";
CM_ SG_ 127 MsgCrc "mEbcm2L_WhlSpd Message Checksum (E2E data ID: 0x2A)";
CM_ SG_ 770 VcuStateShtdwn "VCU Shutdown Sub State";
CM_ SG_ 770 VcuStateInit "VCU Initialization Sub State";
CM_ SG_ 770 AdcuShtdwnRq "Signal from VCU to request ADCU to shutdown.";
CM_ SG_ 770 EstopTest "ESTOP = Estop button is pressed (aka.True/Active/Pressed/Engaged).  OK = Estop button is not pressed (aka. False/NotActive/NotPressed/Disengaged)";
CM_ SG_ 770 EbcmShtdwnRq "Signal is deprecated.  Please use mBrkCtrl.EbcmShtdwnRq.  Retained for backward compatibility.";
CM_ SG_ 770 MsgCrc "mVcuSys Message Checksum (E2E data ID: 0x58)";
CM_ BO_ 516 "VCU Faults Reporting";
CM_ SG_ 516 Flt_LocFcmCan "Loss of Com Fault on FCM on CAN";
CM_ BO_ 514 "Vehicle Level State Data.";
CM_ SG_ 514 Invld_GearRq "Invalid Gear Transition is being requested by Controlling Source (AD / TO / LOS)";
CM_ SG_ 514 EstopDetected "Indication that Estop has been detected.";
CM_ SG_ 514 ArbVehSpdValid "Validity for Arbitrated Vehicle Speed.";
CM_ SG_ 514 ArbVehSpd "VCU Arbitrated Vehicle Speed";
CM_ SG_ 514 MsgCrc "mVehState Message Checksum (E2E data ID: 0x50)";
CM_ SG_ 514 CrashSns "Crash condition has been sensed.";
CM_ BO_ 512 "Status of Exterior Lights";
CM_ SG_ 512 LightTurnRearRStat "Actual Status of Right Rear Turn Lamp.";
CM_ SG_ 512 LightTurnRearLStat "Actual Status of Left Rear Turn Lamp.";
CM_ SG_ 512 LightTurnFrontRStat "Actual Status of Right Front Turn Lamp.";
CM_ SG_ 512 LightTurnFrontLStat "Actual Status of Left Front Turn Lamp.";
CM_ SG_ 512 LightHighStat "Actual High Beam Lamp Status.";
CM_ SG_ 512 LightLow_TailStat "Actual Status of Tail Lamp, Low Beam, and License Lamp.";
CM_ SG_ 512 LightDRLStat "Actual DRL Lamp Status.";
CM_ SG_ 512 LightStopStat "Actual Status of Stop Lamp.";
CM_ SG_ 512 LightChmslStat "Actual CHMSL Lamp Status.";
CM_ SG_ 512 LightRevStat "Actual Status of Reverse Lamp.";
CM_ SG_ 512 HornStat "Actual Horn Status.";
CM_ BO_ 658 "Previously named 'EPAS2'";
CM_ BO_ 123 "Downstream EBCM (Lower)";
CM_ SG_ 123 EbdActv "Electronic Brake Distribution actively reducing braking force.";
CM_ SG_ 123 MsgCrc "mEbcm2L_Stat2  Message Checksum (E2E data ID: 0x27)";
CM_ SG_ 123 EscAvail "EBCM ESC function is available.";
CM_ SG_ 123 AbsAvail "ABS function is available.";
CM_ SG_ 123 EscActv "EBCM ESC function is actuating.";
CM_ SG_ 123 AebRdy "Flag indicating if AEB is available.";
CM_ SG_ 123 AbsActv "ABS actuation in progress.";
BA_DEF_ SG_  "SigType" ENUM  "Default","Range","RangeSigned","ASCII","Discrete","Control","ReferencePGN","DTC","StringDelimiter","StringLength","StringLengthControl","MessageCounter","MessageChecksum";
BA_DEF_ SG_  "Gateway_ID" INT 0 0;
BA_DEF_ SG_  "GenSigEVName" STRING ;
BA_DEF_ SG_  "GenSigILSupport" ENUM  "No","Yes";
BA_DEF_ SG_  "GenSigSendType" ENUM  "Cyclic","OnWrite","OnWriteWithRepetition","OnChange","OnChangeWithRepetition","IfActive","IfActiveWithRepetition","NoSigSendType";
BA_DEF_ SG_  "GenSigStartValue" INT 0 2147483647;
BA_DEF_ BO_  "GenMsgCycleTimeFast" INT 0 3600000;
BA_DEF_ BO_  "GenMsgILSupport" ENUM  "No","Yes";
BA_DEF_ BO_  "GenMsgRequestable" INT 0 1;
BA_DEF_ BO_  "GenMsgSendType" ENUM  "Cyclic","NotUsed","IfActive","On Request","NotUsed","NotUsed","NotUsed","NotUsed","noMsgSendType";
BA_DEF_ BO_  "GenMsgCycleTime" INT 0 3600000;
BA_DEF_  "DBName" STRING ;
BA_DEF_  "BusType" STRING ;
BA_DEF_  "Baudrate" INT 0 0;
BA_DEF_DEF_  "SigType" "Default";
BA_DEF_DEF_  "Gateway_ID" 0;
BA_DEF_DEF_  "GenSigEVName" "Env@Nodename_@Signame";
BA_DEF_DEF_  "GenSigILSupport" "Yes";
BA_DEF_DEF_  "GenSigSendType" "NoSigSendType";
BA_DEF_DEF_  "GenSigStartValue" 0;
BA_DEF_DEF_  "GenMsgCycleTimeFast" 0;
BA_DEF_DEF_  "GenMsgILSupport" "Yes";
BA_DEF_DEF_  "GenMsgRequestable" 1;
BA_DEF_DEF_  "GenMsgSendType" "noMsgSendType";
BA_DEF_DEF_  "GenMsgCycleTime" 0;
BA_DEF_DEF_  "DBName" "";
BA_DEF_DEF_  "BusType" "CAN";
BA_DEF_DEF_  "Baudrate" 500000;
BA_ "DBName" "CAN_AD";
BA_ "GenMsgSendType" BO_ 1544 0;
BA_ "GenMsgCycleTime" BO_ 1544 100;
BA_ "GenMsgSendType" BO_ 1543 0;
BA_ "GenMsgCycleTime" BO_ 1543 100;
BA_ "GenMsgSendType" BO_ 1542 0;
BA_ "GenMsgCycleTime" BO_ 1542 100;
BA_ "GenMsgCycleTimeFast" BO_ 521 50;
BA_ "GenMsgSendType" BO_ 521 0;
BA_ "GenMsgCycleTime" BO_ 521 50;
BA_ "GenMsgCycleTimeFast" BO_ 522 100;
BA_ "GenMsgSendType" BO_ 522 0;
BA_ "GenMsgCycleTime" BO_ 522 100;
BA_ "GenMsgSendType" BO_ 520 0;
BA_ "GenMsgCycleTime" BO_ 520 20;
BA_ "GenMsgSendType" BO_ 289 0;
BA_ "GenMsgCycleTime" BO_ 289 20;
BA_ "GenMsgCycleTimeFast" BO_ 288 500;
BA_ "GenMsgSendType" BO_ 288 0;
BA_ "GenMsgCycleTime" BO_ 288 500;
BA_ "GenMsgCycleTimeFast" BO_ 1541 500;
BA_ "GenMsgSendType" BO_ 1541 0;
BA_ "GenMsgCycleTime" BO_ 1541 500;
BA_ "GenMsgCycleTimeFast" BO_ 1540 500;
BA_ "GenMsgSendType" BO_ 1540 0;
BA_ "GenMsgCycleTime" BO_ 1540 500;
BA_ "GenMsgCycleTimeFast" BO_ 1429 500;
BA_ "GenMsgSendType" BO_ 1429 0;
BA_ "GenMsgCycleTime" BO_ 1429 500;
BA_ "GenMsgCycleTimeFast" BO_ 1428 500;
BA_ "GenMsgSendType" BO_ 1428 0;
BA_ "GenMsgCycleTime" BO_ 1428 500;
BA_ "GenMsgCycleTimeFast" BO_ 1434 500;
BA_ "GenMsgSendType" BO_ 1434 0;
BA_ "GenMsgCycleTime" BO_ 1434 500;
BA_ "GenMsgCycleTimeFast" BO_ 1425 500;
BA_ "GenMsgSendType" BO_ 1425 0;
BA_ "GenMsgCycleTime" BO_ 1425 500;
BA_ "GenMsgCycleTimeFast" BO_ 1437 500;
BA_ "GenMsgSendType" BO_ 1437 0;
BA_ "GenMsgCycleTime" BO_ 1437 500;
BA_ "GenMsgCycleTimeFast" BO_ 1439 500;
BA_ "GenMsgSendType" BO_ 1439 0;
BA_ "GenMsgCycleTime" BO_ 1439 500;
BA_ "GenMsgSendType" BO_ 660 0;
BA_ "GenMsgCycleTime" BO_ 660 10000;
BA_ "GenMsgCycleTimeFast" BO_ 523 100;
BA_ "GenMsgSendType" BO_ 523 0;
BA_ "GenMsgCycleTime" BO_ 523 100;
BA_ "GenMsgCycleTimeFast" BO_ 524 100;
BA_ "GenMsgSendType" BO_ 524 0;
BA_ "GenMsgCycleTime" BO_ 524 100;
BA_ "GenMsgCycleTimeFast" BO_ 1436 500;
BA_ "GenMsgSendType" BO_ 1436 0;
BA_ "GenMsgCycleTime" BO_ 1436 500;
BA_ "GenMsgCycleTimeFast" BO_ 1427 500;
BA_ "GenMsgSendType" BO_ 1427 0;
BA_ "GenMsgCycleTime" BO_ 1427 500;
BA_ "GenMsgCycleTimeFast" BO_ 1433 500;
BA_ "GenMsgSendType" BO_ 1433 0;
BA_ "GenMsgCycleTime" BO_ 1433 500;
BA_ "GenMsgCycleTimeFast" BO_ 1432 500;
BA_ "GenMsgSendType" BO_ 1432 0;
BA_ "GenMsgCycleTime" BO_ 1432 500;
BA_ "GenMsgCycleTimeFast" BO_ 1431 500;
BA_ "GenMsgSendType" BO_ 1431 0;
BA_ "GenMsgCycleTime" BO_ 1431 500;
BA_ "GenMsgCycleTimeFast" BO_ 519 100;
BA_ "GenMsgSendType" BO_ 519 0;
BA_ "GenMsgCycleTime" BO_ 519 100;
BA_ "GenMsgSendType" BO_ 1555 0;
BA_ "GenMsgCycleTime" BO_ 1555 20;
BA_ "GenMsgSendType" BO_ 518 0;
BA_ "GenMsgCycleTime" BO_ 518 10;
BA_ "GenMsgSendType" BO_ 517 0;
BA_ "GenMsgCycleTime" BO_ 517 10;
BA_ "GenMsgCycleTimeFast" BO_ 120 20;
BA_ "GenMsgSendType" BO_ 120 0;
BA_ "GenMsgCycleTime" BO_ 120 20;
BA_ "GenMsgSendType" BO_ 1793 0;
BA_ "GenMsgCycleTime" BO_ 1793 10000;
BA_ "GenMsgCycleTimeFast" BO_ 1553 100;
BA_ "GenMsgSendType" BO_ 1553 0;
BA_ "GenMsgCycleTime" BO_ 1553 100;
BA_ "GenMsgSendType" BO_ 668 0;
BA_ "GenMsgCycleTime" BO_ 668 10000;
BA_ "GenMsgCycleTimeFast" BO_ 2365450241 100;
BA_ "GenMsgSendType" BO_ 2365450241 0;
BA_ "GenMsgCycleTime" BO_ 2365450241 100;
BA_ "GenMsgCycleTimeFast" BO_ 2365446452 62;
BA_ "GenMsgSendType" BO_ 2365446452 0;
BA_ "GenMsgCycleTime" BO_ 2365446452 62;
BA_ "GenMsgCycleTimeFast" BO_ 2365446196 62;
BA_ "GenMsgSendType" BO_ 2365446196 0;
BA_ "GenMsgCycleTime" BO_ 2365446196 62;
BA_ "GenMsgCycleTimeFast" BO_ 2365445939 62;
BA_ "GenMsgSendType" BO_ 2365445939 0;
BA_ "GenMsgCycleTime" BO_ 2365445939 62;
BA_ "GenMsgCycleTimeFast" BO_ 2365445683 62;
BA_ "GenMsgSendType" BO_ 2365445683 0;
BA_ "GenMsgCycleTime" BO_ 2365445683 62;
BA_ "GenMsgSendType" BO_ 129 0;
BA_ "GenMsgCycleTime" BO_ 129 24;
BA_ "GenMsgCycleTimeFast" BO_ 124 12;
BA_ "GenMsgSendType" BO_ 124 0;
BA_ "GenMsgCycleTime" BO_ 124 12;
BA_ "GenMsgCycleTimeFast" BO_ 127 12;
BA_ "GenMsgSendType" BO_ 127 0;
BA_ "GenMsgCycleTime" BO_ 127 12;
BA_ "GenMsgSendType" BO_ 770 0;
BA_ "GenMsgCycleTime" BO_ 770 50;
BA_ "GenMsgSendType" BO_ 516 0;
BA_ "GenMsgCycleTime" BO_ 516 100;
BA_ "GenMsgSendType" BO_ 514 0;
BA_ "GenMsgCycleTime" BO_ 514 50;
BA_ "GenMsgSendType" BO_ 512 0;
BA_ "GenMsgCycleTime" BO_ 512 20;
BA_ "GenMsgSendType" BO_ 658 0;
BA_ "GenMsgCycleTime" BO_ 658 10;
BA_ "GenMsgCycleTimeFast" BO_ 123 12;
BA_ "GenMsgSendType" BO_ 123 0;
BA_ "GenMsgCycleTime" BO_ 123 12;
BA_ "Gateway_ID" SG_ 289 MsgCrc 2418;
BA_ "Gateway_ID" SG_ 289 TO_EstopRq 2176;
BA_ "Gateway_ID" SG_ 289 TO_Steer_Cmd 2321;
BA_ "Gateway_ID" SG_ 289 TO_Accel_Cmd 2320;
BA_ "Gateway_ID" SG_ 289 MsgCntr 2411;
BA_ "Gateway_ID" SG_ 288 TO_cmd_veh_mode 2175;
BA_ "Gateway_ID" SG_ 288 TO_ConnectionStat 2173;
BA_ "Gateway_ID" SG_ 288 TO_dlg_resp_id 2171;
BA_ "Gateway_ID" SG_ 288 TO_dlg_resp_code 2168;
BA_ "GenSigStartValue" SG_ 288 TO_dlg_resp_code 3;
BA_ "Gateway_ID" SG_ 288 VehDirCmd 2181;
BA_ "Gateway_ID" SG_ 288 MsgCrc 2417;
BA_ "Gateway_ID" SG_ 288 MsgCntr 2412;
BA_ "Gateway_ID" SG_ 660 RightEndStopValue 2986;
BA_ "Gateway_ID" SG_ 660 ProgOffset 2984;
BA_ "Gateway_ID" SG_ 660 LeftEndStopValue 2985;
BA_ "Gateway_ID" SG_ 660 MsgCrc 2983;
BA_ "Gateway_ID" SG_ 660 MsgCntr 2982;
BA_ "Gateway_ID" SG_ 660 SwVerRev 2981;
BA_ "Gateway_ID" SG_ 660 SwVerMin 2741;
BA_ "Gateway_ID" SG_ 660 SwVerMaj 2740;
BA_ "Gateway_ID" SG_ 1555 AdcuStatus 1381;
BA_ "Gateway_ID" SG_ 1555 AdcuShtdwnRdy 1380;
BA_ "Gateway_ID" SG_ 1555 AdcuEstopRq 1379;
BA_ "Gateway_ID" SG_ 1555 MsgCrc 1378;
BA_ "Gateway_ID" SG_ 1555 MsgCntr 1377;
BA_ "Gateway_ID" SG_ 1555 TO_Assistance_Rq 2172;
BA_ "Gateway_ID" SG_ 1555 AD_Ready 2170;
BA_ "Gateway_ID" SG_ 1555 AD_Mission_Cmplt 2169;
BA_ "Gateway_ID" SG_ 1793 SwStat 1348;
BA_ "Gateway_ID" SG_ 1793 SwRev 1347;
BA_ "Gateway_ID" SG_ 1793 SwMin 1346;
BA_ "Gateway_ID" SG_ 1793 SwMaj 1345;
BA_ "Gateway_ID" SG_ 129 MsgCrc 2996;
BA_ "Gateway_ID" SG_ 129 MsgCntr 2995;
BA_ "Gateway_ID" SG_ 129 WhlSlipR 946;
BA_ "Gateway_ID" SG_ 129 WhlSlipFR 945;
BA_ "Gateway_ID" SG_ 129 WhlSlipFL 944;
BA_ "Gateway_ID" SG_ 127 MsgCrc 2122;
BA_ "Gateway_ID" SG_ 127 MsgCntr 2103;
BA_ "Gateway_ID" SG_ 770 VcuStateShtdwn 889;
BA_ "Gateway_ID" SG_ 770 VcuStateInit 888;
BA_ "Gateway_ID" SG_ 770 MtrTrqLmtDecel 886;
BA_ "Gateway_ID" SG_ 770 MtrTrqLmtAccel 885;
BA_ "Gateway_ID" SG_ 770 AdcuShtdwnRq 884;
BA_ "Gateway_ID" SG_ 770 EstopTest 883;
BA_ "Gateway_ID" SG_ 770 EbcmShtdwnRq 2435;
BA_ "Gateway_ID" SG_ 770 MsgCrc 2405;
BA_ "Gateway_ID" SG_ 770 MsgCntr 2404;
BA_ "Gateway_ID" SG_ 658 SteerAngle8b 714;
BA_ "Gateway_ID" SG_ 658 ProtectActive 713;
BA_ "Gateway_ID" SG_ 658 FaultLight 705;
BA_ "Gateway_ID" SG_ 658 SelectedMap 703;
BA_ "Gateway_ID" SG_ 123 EbdActv 2965;
BA_ "Gateway_ID" SG_ 123 MsgCrc 672;
VAL_ 521 TargetVehSpd_mps 2047 "SNA" 2046 "Fault" ;
VAL_ 521 AebSrc 15 "FCM + LIDAR + Thermal + LRR" 14 "Thermal + LIDAR + LRR" 13 "FCM + Thermal + LRR" 12 "Thermal + LRR" 11 "FCM + LIDAR + LRR" 10 "LIDAR + LRR" 9 "FCM + LRR" 8 "LRR" 7 "FCM + LIDAR + Thermal" 6 "LIDAR + Thermal" 5 "FCM + Thermal" 4 "Thermal" 3 "FCM + LIDAR" 2 "LIDAR" 1 "FCM" 0 "No AEB Event" ;
VAL_ 521 Aeb_Active 1 "AEB event is Active" 0 "No AEB event active" ;
VAL_ 521 ArbVehSpd_mps_Valid 1 "Valid" 0 "Invalid" ;
VAL_ 521 ArbVehSpd_mps 2047 "SNA" 2046 "Fault" ;
VAL_ 522 BackendTripMeter 65535 "SNA" 65534 "Fault" ;
VAL_ 522 VcuTripMeter 65535 "SNA" 65534 "Fault" ;
VAL_ 522 VehOdo 16777215 "SNA" 16777214 "Fault" ;
VAL_ 289 TO_EstopRq 1 "True" 0 "False" ;
VAL_ 288 TO_cmd_veh_mode 4 "E-Stop" 3 "TeleOps" 2 "Monitor & Assist" 1 "<Unused - AD>" 0 "Unknown" ;
VAL_ 288 TO_ConnectionStat 2 "TeleOps in Session" 1 "Connected to Server" 0 "Disconnected" ;
VAL_ 288 TO_dlg_resp_id 2 "No" 1 "Yes" 0 "No Response / Waiting" ;
VAL_ 288 TO_dlg_resp_code 3 "Default" 1 "OperatorClick" 0 "Waiting" ;
VAL_ 288 VehDirCmd 3 "Drive" 2 "Invalid" 1 "Reverse" 0 "Park" ;
VAL_ 1425 Yaw 32768 "SNA" 32767 "Fault" ;
VAL_ 1437 TimeStamp 65535 "SNA" 65534 "Fault" ;
VAL_ 1437 UTC 16777215 "SNA" 16777214 "Fault" ;
VAL_ 1439 SolutionStatus 2 "RTK Fix" 1 "RTK Float" 0 "None" ;
VAL_ 1439 PositionType 5 "Time only" 4 "GNSS DR" 3 "3D-fix" 2 "2D-fix" 1 "DR only" 0 "None" ;
VAL_ 660 RightEndStopValue 0 "SNA" ;
VAL_ 660 LeftEndStopValue 0 "SNA" ;
VAL_ 660 MsgCntr 21 "Fault" ;
VAL_ 523 Z_Accel_Filt 32768 "SNA" 32767 "Fault" ;
VAL_ 523 Y_Accel_Filt 32768 "SNA" 32767 "Fault" ;
VAL_ 523 X_Accel_Filt 32768 "SNA" 32767 "Fault" ;
VAL_ 524 Z_Angular_Rate_Filt 32768 "SNA" 32767 "Fault" ;
VAL_ 524 Y_Angular_Rate_Filt 32768 "SNA" 32767 "Fault" ;
VAL_ 524 X_Angular_Rate_Filt 32768 "SNA" 32767 "Fault" ;
VAL_ 1436 std_Speed 65535 "SNA" 65534 "Fault" ;
VAL_ 1436 std_North 65535 "SNA" 65534 "Fault" ;
VAL_ 1436 std_Height 65535 "SNA" 65534 "Fault" ;
VAL_ 1436 std_East 65535 "SNA" 65534 "Fault" ;
VAL_ 1427 Roll 32768 "SNA" 32767 "Fault" ;
VAL_ 1427 Pitch 32768 "SNA" 32767 "Fault" ;
VAL_ 519 Flt_EPVMC_Cameras 1 "Fault in Env Perception Camera" 0 "OK" ;
VAL_ 1555 AdcuStatus 3 "Error" 2 "OK" 1 "Init" 0 "NA" ;
VAL_ 1555 AdcuShtdwnRdy 1 "True" 0 "False" ;
VAL_ 1555 AdcuEstopRq 1 "True" 0 "False" ;
VAL_ 1555 TO_Assistance_Rq 2 "Remote Control" 1 "Go / No Go" 0 "No Request" ;
VAL_ 1555 AD_Ready 1 "Ready" 0 "Not Ready" ;
VAL_ 1555 AD_Mission_Cmplt 1 "Complete" 0 "Not Complete" ;
VAL_ 518 Y_Angular_Rate 32768 "SNA" 32767 "Fault" ;
VAL_ 518 X_Angular_Rate 32768 "SNA" 32767 "Fault" ;
VAL_ 518 Z_Angular_Rate 32768 "SNA" 32767 "Fault" ;
VAL_ 517 Z_Accel 32768 "SNA" 32767 "Fault" ;
VAL_ 517 Y_Accel 32768 "SNA" 32767 "Fault" ;
VAL_ 517 X_Accel 32768 "SNA" 32767 "Fault" ;
VAL_ 120 AebSrc 15 "reserved" 14 "reserved" 13 "reserved" 12 "reserved" 11 "reserved" 10 "reserved" 9 "reserved" 8 "reserved" 7 "FCM + LIDAR + Thermal" 6 "LIDAR + Thermal" 5 "FCM + Thermal" 4 "Thermal" 3 "FCM + LIDAR" 2 "LIDAR" 1 "FCM" 0 "No AEB Event" ;
VAL_ 120 AebEvent 1 "Engage AEB" 0 "No AEB Event" ;
VAL_ 120 VehDirCmd 3 "Drive" 2 "Invalid" 1 "Reverse" 0 "Park" ;
VAL_ 120 VehAccelLongCmd 2048 "SNA" 2047 "Fault" ;
VAL_ 120 VehSpdCmd 2047 "Fault" ;
VAL_ 1793 SwStat 1 "Released" 0 "Development" ;
VAL_ 1553 LightTurnCmdR 1 "True" 0 "False" ;
VAL_ 1553 LightTurnCmdL 1 "True" 0 "False" ;
VAL_ 1553 LightHighCmd 1 "True" 0 "False" ;
VAL_ 1553 HornCmd 1 "Horn" 0 "Off" ;
VAL_ 1553 LightHazardCmd 1 "True" 0 "False" ;
VAL_ 2365450241 VscMode 11 "Pause" 10 "Menu" 9 "OK" 4 "Local" 1 "Searching" ;
VAL_ 2365450241 VscEstop 0 "OK" 1 "Estop" ;
VAL_ 2365450241 CtrlMode 2 "Auton" 1 "Shared" 0 "User" ;
VAL_ 2365446452 RightZ_Pos 3 "SNA" 2 "Fault" 1 "Set" 0 "Not Set" ;
VAL_ 2365446452 RightZ_Ntrl 3 "SNA" 2 "Fault" 1 "Set" 0 "Not Set" ;
VAL_ 2365446452 RightZ_Neg 3 "SNA" 2 "Fault" 1 "Set" 0 "Not Set" ;
VAL_ 2365446196 RightY_Pos 3 "SNA" 2 "Fault" 1 "Set" 0 "Not Set" ;
VAL_ 2365446196 RightY_Ntrl 3 "SNA" 2 "Fault" 1 "Set" 0 "Not Set" ;
VAL_ 2365446196 RightY_Neg 3 "SNA" 2 "Fault" 1 "Set" 0 "Not Set" ;
VAL_ 2365446196 RightX_Pos 3 "SNA" 2 "Fault" 1 "Set" 0 "Not Set" ;
VAL_ 2365446196 RightX_Ntrl 3 "SNA" 2 "Fault" 1 "Set" 0 "Not Set" ;
VAL_ 2365446196 RightX_Neg 3 "SNA" 2 "Fault" 1 "Set" 0 "Not Set" ;
VAL_ 2365446196 Btn_4 3 "SNA" 2 "Fault" 1 "Set" 0 "Not Set" ;
VAL_ 2365446196 Btn_3 3 "SNA" 2 "Fault" 1 "Set" 0 "Not Set" ;
VAL_ 2365446196 Btn_2 3 "SNA" 2 "Fault" 1 "Set" 0 "Not Set" ;
VAL_ 2365446196 Btn_1 3 "SNA" 2 "Fault" 1 "Set" 0 "Not Set" ;
VAL_ 2365445939 LeftZ_Pos 3 "SNA" 2 "Fault" 1 "Set" 0 "Not Set" ;
VAL_ 2365445939 LeftZ_Ntrl 3 "SNA" 2 "Fault" 1 "Set" 0 "Not Set" ;
VAL_ 2365445939 LeftZ_Neg 3 "SNA" 2 "Fault" 1 "Set" 0 "Not Set" ;
VAL_ 2365445683 LeftY_Pos 3 "SNA" 2 "Fault" 1 "Set" 0 "Not Set" ;
VAL_ 2365445683 LeftY_Ntrl 3 "SNA" 2 "Fault" 1 "Set" 0 "Not Set" ;
VAL_ 2365445683 LeftY_Neg 3 "SNA" 2 "Fault" 1 "Set" 0 "Not Set" ;
VAL_ 2365445683 LeftX_Pos 3 "SNA" 2 "Fault" 1 "Set" 0 "Not Set" ;
VAL_ 2365445683 LeftX_Ntrl 3 "SNA" 2 "Fault" 1 "Set" 0 "Not Set" ;
VAL_ 2365445683 LeftX_Neg 3 "SNA" 2 "Fault" 1 "Set" 0 "Not Set" ;
VAL_ 2365445683 Btn_Up 3 "SNA" 2 "Fault" 1 "Set" 0 "Not Set" ;
VAL_ 2365445683 Btn_Right 3 "SNA" 2 "Fault" 1 "Set" 0 "Not Set" ;
VAL_ 2365445683 Btn_Left 3 "SNA" 2 "Fault" 1 "Set" 0 "Not Set" ;
VAL_ 2365445683 Btn_Dwn 3 "SNA" 2 "Fault" 1 "Set" 0 "Not Set" ;
VAL_ 129 WhlSlipR 32767 "SNA" ;
VAL_ 129 WhlSlipFR 32767 "SNA" ;
VAL_ 129 WhlSlipFL 32767 "SNA" ;
VAL_ 124 WhlCntR 4095 "SNA" 4094 "Fault" ;
VAL_ 124 WhlCntFR 4095 "SNA" 4094 "Fault" ;
VAL_ 124 WhlCntFL 4095 "SNA" 4094 "Fault" ;
VAL_ 127 WhlSpdR 2047 "SNA" 2046 "Fault" ;
VAL_ 127 WhlSpdFR 2047 "SNA" 2046 "Fault" ;
VAL_ 127 WhlSpdFL 2047 "SNA" 2046 "Fault" ;
VAL_ 770 VcuStateShtdwn 15 "Shutdown_Complete" 14 "Discharge_48Vbus" 13 "Disable_ESS" 12 "<reserved>" 11 "Disable_48V" 10 "Disable_DCDC" 9 "<reserved>" 8 "Disable_EBCM" 7 "Disable_ADCU" 6 "Disable_SBW" 5 "Disable_AVAS" 4 "Disable_12V_Safety" 3 "Disable_WHD" 2 "Cargo_Check" 1 "EPB_Check" 0 "N/A" ;
VAL_ 770 VcuStateInit 15 "<reserved>" 14 "<reserved>" 13 "<reserved>" 12 "Init_Complete" 11 "Init_WHD" 10 "Enbl_12V_Safety" 9 "Init_AVAS" 8 "Init_SBW" 7 "Init_ADCU" 6 "Engage_EPB" 5 "Init_EBCM" 4 "Init_DCDC" 3 "48V_Ready" 2 "Init_ESS" 1 "Init_VCU" 0 "N/A" ;
VAL_ 770 AdcuShtdwnRq 1 "True" 0 "False" ;
VAL_ 770 EstopTest 6 "Fail - SafeCircuit" 7 "N/A" 5 "Fail - OK" 4 "Fail - ESTOP" 3 "Pass" 2 "Pending - OK" 1 "Pending - ESTOP" 0 "Start Test" ;
VAL_ 770 EbcmShtdwnRq 1 "True" 0 "False" ;
VAL_ 516 Flt_InvalidGearRq 1 "Fault" 0 "OK" ;
VAL_ 516 Flt_LocEpb 3 "Stored" 2 "Safety" 1 "Active" 0 "OK" ;
VAL_ 516 Flt_LocTo 3 "Stored" 2 "Safety" 1 "Active" 0 "OK" ;
VAL_ 516 Flt_LocBe 3 "Stored" 2 "Safety" 1 "Active" 0 "OK" ;
VAL_ 516 Flt_12vSys 1 "Fault" 0 "OK" ;
VAL_ 516 Flt_WriteEeprom 1 "Fault" 0 "OK" ;
VAL_ 516 Flt_ReadEeprom 1 "Fault" 0 "OK" ;
VAL_ 516 Flt_BrkSafeSys 1 "Fault" 0 "OK" ;
VAL_ 516 Flt_SafeCircuit 1 "Fault" 0 "OK" ;
VAL_ 516 Flt_MstrSwitch 1 "Fault" 0 "OK" ;
VAL_ 516 Flt_CntctrStat 3 "Unknown" 2 "Stuck Close" 1 "Stuck Open" 0 "OK" ;
VAL_ 516 Flt_BrkPrsr 1 "Fault" 0 "OK" ;
VAL_ 516 Flt_WhdEnbl 1 "Fault" 0 "OK" ;
VAL_ 516 Flt_SbwEnbl 1 "Fault" 0 "OK" ;
VAL_ 516 Flt_SafeSteer 3 "General" 2 "Response" 1 "Command" 0 "OK" ;
VAL_ 516 Flt_SafeProp 3 "General" 2 "Response" 1 "Command" 0 "OK" ;
VAL_ 516 Flt_SafeExtLight 3 "General" 2 "Response" 1 "Command" 0 "OK" ;
VAL_ 516 Flt_EpbSys 1 "Fault" 0 "OK" ;
VAL_ 516 Flt_DcdcEnbl 1 "Fault" 0 "OK" ;
VAL_ 516 Flt_48Volt 2 "Low" 1 "High" 0 "OK" ;
VAL_ 516 Flt_12Volt 2 "Low" 1 "High" 0 "OK" ;
VAL_ 516 Flt_LocWhd 3 "Stored" 2 "Safety" 1 "Active" 0 "OK" ;
VAL_ 516 Flt_LocTc 3 "Stored" 2 "Safety" 1 "Active" 0 "OK" ;
VAL_ 516 Flt_LocSbw 3 "Stored" 2 "Safety" 1 "Active" 0 "OK" ;
VAL_ 516 Flt_LocAVAS 3 "Stored" 2 "Safety" 1 "Active" 0 "OK" ;
VAL_ 516 Flt_LocVsc 3 "Stored" 2 "Safety" 1 "Active" 0 "OK" ;
VAL_ 516 Flt_LocEss 3 "Stored" 2 "Safety" 1 "Active" 0 "OK" ;
VAL_ 516 Flt_LocEbcm2 3 "Stored" 2 "Safety" 1 "Active" 0 "OK" ;
VAL_ 516 Flt_LocEbcm1 3 "Stored" 2 "Safety" 1 "Active" 0 "OK" ;
VAL_ 516 Flt_LocLrr 1 "Fault" 0 "OK" ;
VAL_ 516 Flt_KeypadLight 1 "Fault" 0 "OK" ;
VAL_ 516 Flt_KeypadC 1 "Fault" 0 "OK" ;
VAL_ 516 Flt_Keypad4 1 "Fault" 0 "OK" ;
VAL_ 516 Flt_LocFcmCan 1 "Fault" 0 "OK" ;
VAL_ 516 Flt_ImuRst 1 "Fault" 0 "OK" ;
VAL_ 516 Flt_ImuSns 1 "Fault" 0 "OK" ;
VAL_ 516 Flt_Bay2Pwr12v 1 "Fault" 0 "OK" ;
VAL_ 516 Flt_Bay2MtrPos 1 "Fault" 0 "OK" ;
VAL_ 516 Flt_Bay2Mtr 1 "Fault" 0 "OK" ;
VAL_ 516 Flt_Bay2BeltSns 1 "Fault" 0 "OK" ;
VAL_ 516 Flt_Bay1Pwr12v 1 "Fault" 0 "OK" ;
VAL_ 516 Flt_Bay1MtrPos 1 "Fault" 0 "OK" ;
VAL_ 516 Flt_Bay1Mtr 1 "Fault" 0 "OK" ;
VAL_ 516 Flt_Bay1BeltSns 1 "Fault" 0 "OK" ;
VAL_ 514 SBW_RtEndStopReached 1 "True" 0 "False" ;
VAL_ 514 SBW_LfEndStopReached 1 "True" 0 "False" ;
VAL_ 514 EstopDetected 1 "ESTOP" 0 "OK" ;
VAL_ 514 Tether_Connected 1 "Connected" 0 "Disconnected" ;
VAL_ 514 VehParkRq 1 "Park Request" 0 "No Request" ;
VAL_ 514 ArbVehSpdValid 1 "Valid" 0 "Invalid" ;
VAL_ 514 ArbVehSpd 2047 "SNA" 2046 "Fault" ;
VAL_ 514 GearRq 3 "Fwd" 1 "Rvrs" 0 "Park" 2 "Invalid" ;
VAL_ 514 GearChangeParkAllow 1 "Allowed" 0 "Not Allowed" ;
VAL_ 514 TO_Allowed 1 "Allowed" 0 "Not Allowed" ;
VAL_ 514 LOS_Allowed 1 "Allowed" 0 "Not Allowed" ;
VAL_ 514 AD_Allowed 1 "Allowed" 0 "Not Allowed" ;
VAL_ 514 GearChangeDrvRevAllow 1 "Allowed" 0 "Not Allowed" ;
VAL_ 514 GearAct 3 "Fwd" 2 "Ntrl" 1 "Rvrs" 0 "Park" ;
VAL_ 514 CrashSns 1 "True" 0 "False" ;
VAL_ 514 VcuEstopSns 1 "Estop" 0 "OK" ;
VAL_ 514 VehState 15 "Sleep" 13 "PreTripTest" 12 "Service" 11 "Crash" 10 "Shutdown" 9 "AEB" 8 "TO_Ctrl" 7 "Los_Ctrl" 6 "AD_Ctrl" 5 "Delivery_Mode" 4 "Vendor_Ops" 3 "Standby" 2 "System_Init" 1 "Wakeup" 0 "NA" ;
VAL_ 512 LightTurnRearRStat 8 "Open Load" 4 "Short To Ground" 2 "Short To Battery" 1 "On" 0 "Off" ;
VAL_ 512 LightTurnRearLStat 8 "Open Load" 4 "Short To Ground" 2 "Short To Battery" 1 "On" 0 "Off" ;
VAL_ 512 LightTurnFrontRStat 8 "Open Load" 4 "Short To Ground" 2 "Short To Battery" 1 "On" 0 "Off" ;
VAL_ 512 LightTurnFrontLStat 8 "Open Load" 4 "Short To Ground" 2 "Short To Battery" 1 "On" 0 "Off" ;
VAL_ 512 LightHighStat 8 "Open Load" 4 "Short To Ground" 2 "Short To Battery" 1 "On" 0 "Off" ;
VAL_ 512 LightLow_TailStat 8 "Open Load" 4 "Short To Ground" 2 "Short To Battery" 1 "On" 0 "Off" ;
VAL_ 512 LightDRLStat 8 "Open Load" 2 "Short To Battery" 1 "On" 0 "Off" 4 "Short To Ground" ;
VAL_ 512 LightStopStat 8 "Open Load" 4 "Short To Ground" 2 "Short To Battery" 1 "On" 0 "Off" ;
VAL_ 512 LightChmslStat 8 "Open Load" 3 "Short To Ground" 2 "Short To Battery" 1 "On" 0 "Off" ;
VAL_ 512 LightRevStat 8 "Open Load" 4 "Short To Ground" 2 "Short To Battery" 1 "On" 0 "Off" ;
VAL_ 512 HornStat 8 "Open Load" 4 "Short To Ground" 2 "Short To Battery" 1 "On" 0 "Off" ;
VAL_ 658 ProtectActive 1 "True" 0 "False" ;
VAL_ 658 RemModeActive 1 "True" 0 "False" ;
VAL_ 658 RightStopLmt 1 "True" 0 "False" ;
VAL_ 658 OverTemp 1 "True" 0 "False" ;
VAL_ 658 LeftStopLmt 1 "True" 0 "False" ;
VAL_ 658 RS232Mode 1 "False" 0 "True" ;
VAL_ 658 MtrAdjust 3 "SNA" 2 "CCW" 1 "CW" 0 "Idle" ;
VAL_ 658 HostMode 1 "False" 0 "True" ;
VAL_ 658 FaultLight 1 "Fault" 0 "OK" ;
VAL_ 658 FltCode 0 "OK" 111 "Internal Error" 110 "Flt_OverTmpr" 109 "Flt_OverCurr" 108 "Flt_ClutchCurrHigh" 107 "Flt_ClutchOpen" 106 "Flt_MtrCurrHigh" 105 "Flt_MtrCurrLow" 104 "Flt_MtrPwrHigh" 103 "Flt_CurrSnsr" 102 "Flt_TrqSnsr" 101 "Flt_TrqSnsrOpen" 100 "Flt_UnderVolt" ;
VAL_ 123 EbdActv 1 "EBD Active" 0 "EBD not active" ;
VAL_ 123 EscAvail 2 "Level_2" 1 "Level_1" 0 "Not Avail" ;
VAL_ 123 TcsAvail 1 "Available" 0 "Not Avail" ;
VAL_ 123 AbsAvail 1 "Available" 0 "Not Avail" ;
VAL_ 123 TcsActv 1 "True" 0 "False" ;
VAL_ 123 EscActv 1 "True" 0 "False" ;
VAL_ 123 AebRdy 1 "True" 0 "False" ;
VAL_ 123 AbsActv 1 "True" 0 "False" ;
VAL_ 123 VehSpdEbcm 2047 "SNA" 2046 "Fault" ;
VAL_ 123 ToShtdwn 4 "True" 3 "Pend_20s" 2 "Pend_10s" 1 "Pend_1s" 0 "False" ;
VAL_ 123 HoldStat 3 "PlusControl" 2 "Release" 1 "Controlled" 0 "No_Hold_Requested" ;
SIG_GROUP_ 1544 mGpdAntStatus 1 : RelPosLength;
SIG_GROUP_ 1543 mGpsLonRoverHP 1 : VehLonRover_hi VehLonRover_lo;
SIG_GROUP_ 1542 mGpsLatRoverHP 1 : VehLatRover_lo VehLatRover_hi;
SIG_GROUP_ 521 mVehState3 1 : TargetVehSpd_mps ROI AebSrc Aeb_Active MsgCrc MsgCntr ArbVehSpd_mps_Valid ArbVehSpd_mps;
SIG_GROUP_ 522 mVehOdo 1 : VehOdo VcuTripMeter BackendTripMeter;
SIG_GROUP_ 520 mVehState2 1 : maxAccelAvail ActGndWhlAng maxDecelAvail MsgCntr MsgCrc maxSpeedAllowed;
SIG_GROUP_ 289 mVehCtrlTORq 1 : MsgCntr TO_Accel_Cmd TO_Steer_Cmd TO_EstopRq MsgCrc;
SIG_GROUP_ 288 mTOStat 1 : MsgCntr MsgCrc VehDirCmd TO_dlg_resp_code TO_dlg_resp_id TO_ConnectionStat TO_cmd_veh_mode;
SIG_GROUP_ 1541 mGpsLonHP 1 : VehLon_lo VehLon_hi;
SIG_GROUP_ 1540 mGpsLatHP 1 : VehLat_lo VehLat_hi;
SIG_GROUP_ 1429 mGpsSpdNorth 1 : NorthVelocity;
SIG_GROUP_ 1428 mGpsSpdEast 1 : EastVelocity;
SIG_GROUP_ 1434 mGpsAtt 1 : Pitch_SD Roll_SD Yaw_SD;
SIG_GROUP_ 1425 mGpsSpdVeh 1 : gSpeed Yaw;
SIG_GROUP_ 1437 mGpsTime 1 : TimeStamp UTC;
SIG_GROUP_ 1439 mGpsStatus 1 : SolutionStatus PositionType nSattellites;
SIG_GROUP_ 660 mSbwSys_Allied 1 : RightEndStopValue ProgOffset LeftEndStopValue MsgCrc MsgCntr SwVerRev SwVerMin SwVerMaj;
SIG_GROUP_ 523 mVcuImuLinAccel_Filt 1 : Z_Accel_Filt Y_Accel_Filt X_Accel_Filt MsgCrc MsgCntr;
SIG_GROUP_ 524 mVcuImuAngVel_Filt 1 : Z_Angular_Rate_Filt Y_Angular_Rate_Filt X_Angular_Rate_Filt MsgCrc MsgCntr;
SIG_GROUP_ 1436 mGpsStdErr 1 : std_Speed std_North std_Height std_East;
SIG_GROUP_ 1427 mGpsHead 1 : Roll Pitch VehHead;
SIG_GROUP_ 1433 mGpsHeight 1 : Height;
SIG_GROUP_ 1432 mGpsLat 1 : VehLat;
SIG_GROUP_ 1431 mGpsLong 1 : VehLong;
SIG_GROUP_ 519 mAdcuFaults 1 : Flt_EPVMC_Cameras;
SIG_GROUP_ 1555 mAdcuStat 1 : AdcuStatus AdcuShtdwnRdy AdcuEstopRq MsgCrc MsgCntr TO_Assistance_Rq AD_Ready AD_Mission_Cmplt;
SIG_GROUP_ 518 mVcuImuAngVel 1 : MsgCrc MsgCntr Y_Angular_Rate X_Angular_Rate Z_Angular_Rate;
SIG_GROUP_ 517 mVcuImuLinAccel 1 : MsgCrc MsgCntr Z_Accel Y_Accel X_Accel;
SIG_GROUP_ 120 mVehCtrlADRq 1 : MsgCntr MsgCrc VehSpdCmd VehAccelLongCmd VehDirCmd VehRoadWhlAngleCmd b_High_Deceleration_Flag AebEvent AebSrc;
SIG_GROUP_ 1793 mAdcuSwVer 1 : SwStat SwRev SwMin SwMaj;
SIG_GROUP_ 1553 mExtLightsADRq 1 : LightTurnCmdR LightTurnCmdL LightHighCmd HornCmd LightHazardCmd;
SIG_GROUP_ 668 mSbwCals 1 : MsgCrc MsgCntr RightEndStopVal LeftEndStopVal CenterBit;
SIG_GROUP_ 2365450241 mVscStat 1 : VscMode VscEstop CtrlMode;
SIG_GROUP_ 2365446452 mRightJoyStat2 1 : RightZ_Value RightZ_Pos RightZ_Ntrl RightZ_Neg;
SIG_GROUP_ 2365446196 mRightJoyStat 1 : RightY_Value RightY_Pos RightY_Ntrl RightY_Neg RightX_Value RightX_Pos RightX_Ntrl RightX_Neg Btn_4 Btn_3 Btn_2 Btn_1;
SIG_GROUP_ 2365445939 mLeftJoyStat2 1 : LeftZ_Value LeftZ_Pos LeftZ_Ntrl LeftZ_Neg;
SIG_GROUP_ 2365445683 mLeftJoyStat 1 : LeftY_Value LeftY_Pos LeftY_Ntrl LeftY_Neg LeftX_Value LeftX_Pos LeftX_Ntrl LeftX_Neg Btn_Up Btn_Right Btn_Left Btn_Dwn;
SIG_GROUP_ 129 mEbcm2L_WhlSlip 1 : MsgCrc MsgCntr WhlSlipR WhlSlipFR WhlSlipFL;
SIG_GROUP_ 124 mEbcm2L_WhlCnt 1 : WhlCntR WhlCntFR WhlCntFL;
SIG_GROUP_ 127 mEbcm2L_WhlSpd 1 : MsgCrc MsgCntr WhlSpdR WhlSpdFR WhlSpdFL;
SIG_GROUP_ 770 mVcuSys 1 : VcuStateShtdwn VcuStateInit MtrTrqLmtDecel MtrTrqLmtAccel AdcuShtdwnRq EstopTest EbcmShtdwnRq MsgCrc MsgCntr;
SIG_GROUP_ 516 mVcuFaults 1 : Flt_LocTo Flt_Bay2Pwr12v Flt_WriteEeprom Flt_ImuSns Flt_LocFcmCan Flt_LocBe Flt_ImuRst Flt_LocEbcm1 Flt_12vSys Flt_Keypad4 Flt_LocVsc Flt_LocAdcu Flt_LocLrr Flt_KeypadC Flt_Bay1BeltSns Flt_Bay1Mtr Flt_Bay1MtrPos Flt_Bay2Mtr Flt_Bay2MtrPos Flt_Bay1Pwr12v Flt_Bay2BeltSns Flt_KeypadLight Flt_BrkSafeSys Flt_LocEbcm2 Flt_SafeCircuit Flt_LocEss Flt_MstrSwitch Flt_LocAVAS Flt_EpbSys Flt_SafeExtLight Flt_SafeProp Flt_WhdEnbl Flt_CntctrStat Flt_BrkPrsr Flt_SbwEnbl Flt_LocSbw Flt_48Volt Flt_12Volt Flt_LocTc Flt_LocWhd Flt_DcdcEnbl Flt_SafeSteer Flt_ReadEeprom Flt_LocEpb Flt_InvalidGearRq;
SIG_GROUP_ 514 mVehState 1 : SBW_RtEndStopReached SBW_LfEndStopReached Invld_GearRq EstopDetected Tether_Connected VehParkRq ArbVehSpdValid ArbVehSpd GearRq GearChangeParkAllow TO_Allowed LOS_Allowed AD_Allowed GearChangeDrvRevAllow GearAct MsgCrc MsgCntr VehDte LvVolt CrashSns VcuEstopSns VehState;
SIG_GROUP_ 512 mExtLightStat 1 : MsgCntr LightTurnRearRStat LightTurnRearLStat LightTurnFrontRStat LightTurnFrontLStat LightHighStat LightLow_TailStat LightDRLStat LightStopStat LightChmslStat LightRevStat HornStat;
SIG_GROUP_ 658 mSbwStat2 1 : SteerAngle8b ProtectActive RemModeActive RightStopLmt OverTemp LeftStopLmt RS232Mode MtrAdjust HostMode FaultLight FltCode SelectedMap SteerAngle;
SIG_GROUP_ 123 mEbcm2L_Stat2 1 : EbdActv MsgCrc EscAvail TcsAvail AbsAvail TcsActv EscActv AebRdy AbsActv VehSpdEbcm ToShtdwn HoldStat MsgCntr LvVolt MtrCurrEst;
